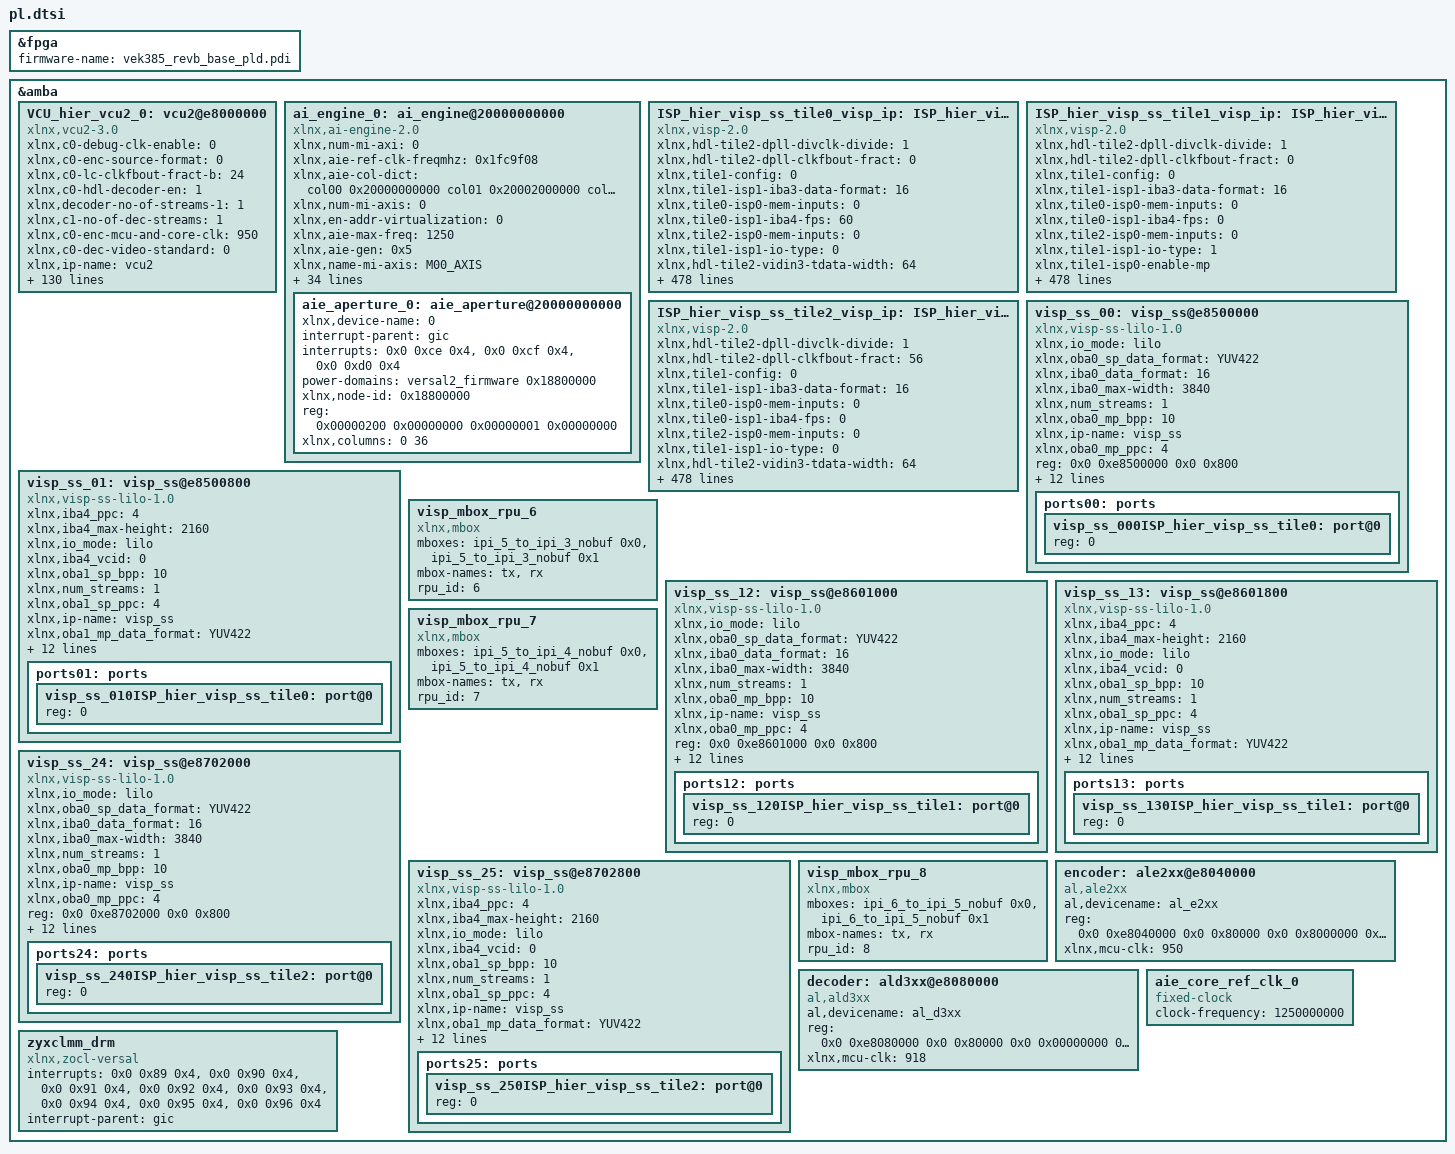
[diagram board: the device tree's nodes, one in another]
/dts-v1/;
/plugin/;
&fpga {
	firmware-name = "vek385_revb_base_pld.pdi";
};

&amba {
	VCU_hier_vcu2_0: vcu2@e8000000 {
		xlnx,c0-debug-clk-enable = <0>;
		xlnx,c0-enc-source-format = <0>;
		xlnx,c0-lc-clkfbout-fract-b = <24>;
		xlnx,c0-hdl-decoder-en = <1>;
		xlnx,decoder-no-of-streams-1 = <1>;
		xlnx,c1-no-of-dec-streams = <1>;
		xlnx,c0-enc-mcu-and-core-clk = <950>;
		xlnx,c0-dec-video-standard = <0>;
		xlnx,ip-name = "vcu2";
		#size-cells = <2>;
		reg = <0x0 0xe8000000 0x0 0x100000>;
		xlnx,encoder-resolution = "4096X2160";
		xlnx,c1-axi-slave-clk = <167>;
		xlnx,c0-enable-seperate-interrupts;
		#address-cells = <2>;
		xlnx,decoder-frequency-1 = <1050>;
		xlnx,c1-debug-clk-enable = <0>;
		xlnx,actual-c1-dec-mcu-and-core-clk = <0x36b6ce30>;
		xlnx,decoder-color-depth = <12>;
		xlnx,c1-lc-clkin-period-a = <0x7270e0>;
		xlnx,c0-dec-coding-type = <0>;
		xlnx,c0-enc-fps = <3>;
		xlnx,c0-hdl-enable-encoder-jtag = <0>;
		xlnx,decoder-resolution-1 = "4096X2160";
		xlnx,c1-lc-clkin-period-b = <0x7270e0>;
		xlnx,c1-hdl-enable-encoder-jtag = <0>;
		xlnx,c1-enc-fps = <3>;
		xlnx,c1-enable-encoder;
		xlnx,c1-dec-coding-type = <0>;
		xlnx,decoder-color-format-1 = <444>;
		xlnx,c1-hdl-encoder-en = <1>;
		xlnx,c0-en-debug-clk;
		xlnx,c0-enable-encoder-jtag;
		xlnx,c0-enc-color-format = <3>;
		xlnx,c1-lc-clkout-divide2-a = <4>;
		xlnx,actual-c1-axi-slave-clk = <0x9f2b120>;
		xlnx,enable-instance1 = <0>;
		xlnx,c1-lc-divclk-divide-a = <2>;
		xlnx,c1-lc-clkout-divide2-b = <3>;
		compatible = "xlnx,vcu2-3.0";
		xlnx,c0-dec-color-depth = <2>;
		xlnx,encoder-frame-per-second-1 = <60>;
		xlnx,c1-lc-divclk-divide-b = <1>;
		xlnx,c1-enc-source-format = <0>;
		xlnx,c1-dec-color-depth = <2>;
		xlnx,c0-dec-mcu-and-core-clk = <918>;
		xlnx,actual-c0-enc-mcu-and-core-clk = <0x389f8b60>;
		xlnx,c0-enable-encoder;
		xlnx,decoder-frequency = <1050>;
		xlnx,c0-hdl-enc-enable-low-latency-mode = <0>;
		xlnx,c0-hdl-encoder-en = <1>;
		xlnx,c1-hdl-enc-enable-low-latency-mode = <0>;
		xlnx,c0-no-of-enc-streams = <1>;
		xlnx,encoder-frequency = <950>;
		xlnx,encoder-coding-standard = "HEVC";
		xlnx,c1-dec-enable-low-latency-mode;
		xlnx,c0-enc-enable-low-latency-mode;
		xlnx,c0-enc-video-standard = <0>;
		xlnx,c1-enc-color-format = <3>;
		xlnx,c0-axi-slave-clk = <167>;
		xlnx,encoder-color-format = <444>;
		xlnx,c0-hdl-enable-decoder-jtag = <0>;
		xlnx,c1-hdl-enable-decoder-jtag = <0>;
		xlnx,c0-lc-clkfbout-mult-a = <55>;
		xlnx,new-param-for-image = <0>;
		xlnx,target-board = <0>;
		xlnx,c0-ref-clk = <0x7f27450>;
		xlnx,c0-lc-clkfbout-mult-b = <21>;
		xlnx,encoder-frame-per-second = <60>;
		xlnx,c1-ref-clk = <0x7f27450>;
		xlnx,c1-dec-frame-size = <5>;
		xlnx,c0-enable-decoder-jtag;
		xlnx,c0-dec-color-format = <3>;
		xlnx,num-of-instances = <0>;
		xlnx,c1-dec-video-standard = <0>;
		xlnx,encoder-color-format-1 = <444>;
		xlnx,actual-c0-axi-slave-clk = <0x9f2b120>;
		xlnx,name = "VCU_hier_vcu2_0";
		xlnx,enable-instance0-dpll;
		xlnx,c1-lc-clkout-divide3-a = <22>;
		xlnx,c1-lc-clkfbout-fract-a = <5>;
		xlnx,actual-c0-dec-mcu-and-core-clk = <0x36b6ce30>;
		xlnx,c1-lc-clkfbout-fract-b = <24>;
		xlnx,c1-enable-seperate-interrupts;
		xlnx,design-topology = <0>;
		xlnx,c0-dec-frame-size = <5>;
		xlnx,encoder-no-of-streams-1 = <1>;
		xlnx,c1-no-of-enc-streams = <1>;
		xlnx,c1-dec-color-format = <3>;
		xlnx,decoder-color-format = <444>;
		xlnx,c0-dec-fps = <3>;
		xlnx,decoder-frame-per-second = <60>;
		xlnx,decoder-coding-standard-1 = "HEVC";
		xlnx,c1-enable-decoder;
		xlnx,c1-dec-fps = <3>;
		xlnx,edk-iptype = "PERIPHERAL";
		xlnx,nsu-only;
		xlnx,encoder-frequency-1 = <950>;
		xlnx,encoder-coding-standard-1 = "HEVC";
		xlnx,encoder-color-depth = <12>;
		xlnx,c1-enc-mcu-and-core-clk = <950>;
		xlnx,c0-enc-coding-type = <0>;
		xlnx,c1-enc-frame-size = <5>;
		xlnx,c1-enc-coding-type = <0>;
		xlnx,c1-enable-encoder-jtag;
		xlnx,c0-lc-clkout-divide2-a = <4>;
		xlnx,c1-enc-video-standard = <0>;
		xlnx,c0-lc-clkout-divide2-b = <3>;
		xlnx,decoder-color-depth-1 = <12>;
		xlnx,c0-enable-decoder;
		xlnx,c0-hdl-dec-enable-low-latency-mode = <0>;
		xlnx,encoder-color-depth-1 = <12>;
		xlnx,c1-lc-clkfbout-mult-a = <55>;
		xlnx,c1-hdl-dec-enable-low-latency-mode = <0>;
		xlnx,c0-no-of-dec-streams = <1>;
		xlnx,c0-enc-color-depth = <2>;
		xlnx,decoder-coding-standard = "HEVC";
		xlnx,c1-lc-clkfbout-mult-b = <21>;
		xlnx,c1-enc-color-depth = <2>;
		xlnx,c0-dec-enable-low-latency-mode;
		xlnx,c0-enc-frame-size = <5>;
		xlnx,decoder-resolution = "4096X2160";
		xlnx,c1-en-debug-clk;
		xlnx,c1-enc-enable-low-latency-mode;
		xlnx,c0-lc-divclk-divide-a = <2>;
		xlnx,c0-lc-divclk-divide-b = <1>;
		xlnx,c0-lc-clkin-period-a = <0x7270e0>;
		xlnx,c1-hdl-decoder-en = <1>;
		xlnx,c1-dec-mcu-and-core-clk = <918>;
		xlnx,c0-lc-clkin-period-b = <0x7270e0>;
		xlnx,actual-c1-enc-mcu-and-core-clk = <0x389f8b60>;
		xlnx,decoder-no-of-streams = <1>;
		xlnx,c1-enable-decoder-jtag;
		xlnx,encoder-resolution-1 = "4096X2160";
		xlnx,encoder-no-of-streams = <1>;
		#clock-cells = <1>;
		xlnx,decoder-frame-per-second-1 = <60>;
		xlnx,c0-lc-clkout-divide3-a = <22>;
		xlnx,c0-lc-clkfbout-fract-a = <5>;
	};
	ai_engine_0: ai_engine@20000000000 {
		xlnx,num-mi-axi = <0>;
		compatible = "xlnx,ai-engine-2.0" , "xlnx,ai-engine-v2.0";
		xlnx,aie-ref-clk-freqmhz = <0x1fc9f08>;
		xlnx,aie-col-dict = "col00 0x20000000000 col01 0x20002000000 col02 0x20004000000 col03 0x20006000000 col04 0x20008000000 col05 0x2000A000000 col06 0x2000C000000 col07 0x2000E000000 col08 0x20010000000 col09 0x20012000000 col10 0x20014000000 col11 0x20016000000 col12 0x20018000000 col13 0x2001A000000 col14 0x2001C000000 col15 0x2001E000000 col16 0x20020000000 col17 0x20022000000 col18 0x20024000000 col19 0x20026000000 col20 0x20028000000 col21 0x2002A000000 col22 0x2002C000000 col23 0x2002E000000 col24 0x20030000000 col25 0x20032000000 col26 0x20034000000 col27 0x20036000000 col28 0x20038000000 col29 0x2003A000000 col30 0x2003C000000 col31 0x2003E000000 col32 0x20040000000 col33 0x20042000000 col34 0x20044000000 col35 0x20046000000";
		xlnx,num-mi-axis = <0>;
		xlnx,en-addr-virtualization = <0>;
		xlnx,aie-max-freq = <1250>;
		xlnx,aie-gen = /bits/ 8 <0x5>;
		xlnx,name-mi-axis = "M00_AXIS";
		xlnx,mem-rows = /bits/ 8 <1 2>;
		xlnx,mi-destid-pins;
		xlnx,ip-name = "ai_engine";
		#size-cells = <2>;
		xlnx,num-si-axi = <1>;
		xlnx,fast-pm-write;
		reg = <0x00000200 0x00000000 0x00000001 0x00000000>;
		clocks = <&aie_core_ref_clk_0>;
		xlnx,num-noc-axis-clks = <0>;
		ranges;
		xlnx,num-clks = <0>;
		xlnx,partition-enabled = <0>;
		#address-cells = <2>;
		xlnx,num-si-axis = <0>;
		xlnx,name-mi-axi = "M00_AXI";
		xlnx,num-column = <1>;
		xlnx,aie-core-ref-ctrl-freqmhz = <1250>;
		xlnx,clk-names = "aclk0";
		xlnx,name-si-axis = "S00_AXIS";
		xlnx,fast-dm-write;
		xlnx,edk-iptype = "PERIPHERAL";
		xlnx,selected-nsu = <0>;
		xlnx,available-nsu = "NOC2_NSU128_X0Y6 0x20006000000 NOC2_NSU128_X2Y6 0x2000e000000 NOC2_NSU128_X3Y6 0x20016000000 NOC2_NSU128_X8Y7 0x2001e000000 NOC2_NSU128_X9Y6 0x20026000000 NOC2_NSU128_X10Y7 0x2002e000000 NOC2_NSU128_X11Y6 0x20036000000 NOC2_NSU128_X12Y6 0x2003e000000 NOC2_NSU128_X13Y6 0x20046000000";
		clock-names = "aclk0";
		power-domains = <&versal2_firmware 0x18800000>;
		xlnx,num-trig-in = <0>;
		xlnx,nsu-dict = "NOC2_NSU128_X0Y6 0x20006000000 NOC2_NSU128_X2Y6 0x2000e000000 NOC2_NSU128_X3Y6 0x20016000000 NOC2_NSU128_X8Y7 0x2001e000000 NOC2_NSU128_X9Y6 0x20026000000 NOC2_NSU128_X10Y7 0x2002e000000 NOC2_NSU128_X11Y6 0x20036000000 NOC2_NSU128_X12Y6 0x2003e000000 NOC2_NSU128_X13Y6 0x20046000000";
		xlnx,en-ext-rst = <0>;
		xlnx,num-trig-out = <0>;
		xlnx,core-rows = /bits/ 8 <3 4>;
		xlnx,shim-rows = /bits/ 8 <0 1>;
		xlnx,name-si-axi = "S00_AXI";
		xlnx,start-column = <0>;
		xlnx,name = "ai_engine_0";
		xlnx,aie-site = "AIE2PS";
		aie_aperture_0: aie_aperture@20000000000 {
			xlnx,device-name = <0>;
			interrupt-parent = <&gic>;
			interrupts = <0x0 0xce 0x4>, <0x0 0xcf 0x4>, <0x0 0xd0 0x4>;
			#address-cells = <2>;
			power-domains = <&versal2_firmware 0x18800000>;
			xlnx,node-id = <0x18800000>;
			#size-cells = <2>;
			interrupt-names = "interrupt1" , "interrupt2" , "interrupt3";
			reg = <0x00000200 0x00000000 0x00000001 0x00000000>;
			xlnx,columns = < 0 36 >;
		};
	};
	ISP_hier_visp_ss_tile0_visp_ip: ISP_hier_visp_ss_tile0_visp_ip@e8500000 {
		xlnx,hdl-tile2-dpll-divclk-divide = <1>;
		xlnx,hdl-tile2-dpll-clkfbout-fract = <0>;
		xlnx,tile1-config = <0>;
		xlnx,tile1-isp1-iba3-data-format = <16>;
		xlnx,tile0-isp0-mem-inputs = <0>;
		xlnx,tile0-isp1-iba4-fps = <60>;
		xlnx,tile2-isp0-mem-inputs = <0>;
		xlnx,tile1-isp1-io-type = <0>;
		xlnx,hdl-tile2-vidin3-tdata-width = <64>;
		xlnx,hdl-tile0-vidin0-tuser-width = <96>;
		xlnx,debug-tile2-iba3-bypass = <0>;
		xlnx,debug-tile0-clk-src-dpll;
		xlnx,tile1-isp0-iba3-vcid = <0>;
		xlnx,tile1-isp0-oba0-mp-y;
		xlnx,tile2-isp0-iba1-res-hor = <3840>;
		xlnx,tile0-common-iba3-ppc = <4>;
		reg = <0x0 0xe8500000 0x0 0x100000>;
		xlnx,tile0-isp0-iba3-data-format = <16>;
		xlnx,tile1-isp0-iba1-fps = <0>;
		xlnx,tile2-vidout01-tdata-width = <120>;
		xlnx,tile2-isp0-iba2-data-format = <16>;
		xlnx,hdl-tile0-dpll-clkin-period = <0x72719b>;
		xlnx,tile2-common-iba3-ppc = <4>;
		xlnx,tile1-isp1-oba1-mp-bpp = <10>;
		xlnx,tile0-enable;
		xlnx,tile1-isp0-iba0-res-ver = <2160>;
		xlnx,hdl-tile1-vidin0-tdata-width = <64>;
		xlnx,tile0-dpll-divclk-divide = <1>;
		xlnx,tile0-isp0-core-clk = <0x23988c80>;
		xlnx,tile1-isp0-iba0-vcid = <0>;
		xlnx,hdl-tile1-vidout02-bpp = <10>;
		xlnx,hdl-tile0-vidin4-ppc = <4>;
		xlnx,debug-tile1-apb-clk-src-axi;
		xlnx,tile2-isp0-netfps = <0>;
		xlnx,tile2-isp1-oba1-sp-y;
		xlnx,tile0-isp1-oba1-ppc = <4>;
		xlnx,tile0-vidin3-tdata-width = <64>;
		xlnx,hdl-tile2-isp1-iba4-res-hor = <3840>;
		xlnx,tile0-isp1-iba4-res-hor = <3840>;
		xlnx,tile1-common-iba3-res-ver = <2160>;
		xlnx,hdl-tile1-vidout11-bpp = <10>;
		xlnx,debug-tile2-iba1-bypass = <0>;
		xlnx,hdl-tile1-vidout12-ppc = <4>;
		xlnx,tile2-isp0-iba2-vcid = <0>;
		xlnx,tile2-isp0-oba0-sp-rgb888;
		xlnx,tile0-isp0-iba3-fps = <0>;
		xlnx,hdl-tile1-vidin3-data-format = <16>;
		xlnx,tile1-vidin0-tuser-width = <96>;
		xlnx,tile2-isp0-iba1-res-ver = <2160>;
		xlnx,tile0-isp1-io-type = <1>;
		xlnx,tile0-isp1-mem-inputs = <0>;
		xlnx,tile1-isp0-actual-core-clk = <0x23c31ef0>;
		xlnx,hdl-llpath0-tile = <3>;
		xlnx,tile0-common-iba3-data-format = <16>;
		xlnx,tile0-isp0-oba0-sp-bpp = <10>;
		xlnx,tile0-isp1-iba4-ppc = <4>;
		xlnx,tile1-isp0-oba0-sp-y;
		xlnx,debug-clock-gate = <0>;
		xlnx,tile2-isp1-mem-inputs = <0>;
		xlnx,hdl-tile2-isp1-iba4-vcid = <0>;
		xlnx,hdl-tile0-vidin0-data-format = <16>;
		xlnx,tile2-vidin0-tdata-width = <64>;
		xlnx,tile2-common-iba3-res-hor = <3840>;
		xlnx,tile0-isp1-oba1-sp-rgb888;
		xlnx,tile2-ref-clk = <0x7f27450>;
		xlnx,name = "ISP_hier_visp_ss_tile0_visp_ip";
		xlnx,tile1-isp1-oba1-sp-yuv422;
		xlnx,tile1-isp0-iba1-ppc = <4>;
		xlnx,hdl-tile2-isp0-iba0-res-hor = <3840>;
		xlnx,hdl-tile0-vidout02-bpp = <10>;
		xlnx,tile0-isp0-iba0-res-hor = <3840>;
		xlnx,hdl-tile2-vidin2-tdata-width = <64>;
		xlnx,debug-tile1-iba3-bypass = <0>;
		xlnx,tile0-isp0-oba0-ppc = <4>;
		xlnx,tile0-isp1-iba4-res-ver = <2160>;
		xlnx,hdl-tile1-vidin4-ppc = <4>;
		xlnx,tile0-isp0-iba2-data-format = <16>;
		xlnx,tile0-isp0-oba0-mp-bpp = <10>;
		xlnx,is-hierarchy;
		xlnx,tile2-isp0-iba1-data-format = <16>;
		xlnx,hdl-tile1-dpll-clkfbout-mult = <18>;
		xlnx,hdl-tile0-vidin1-ppc = <4>;
		xlnx,tile0-dpll-clkout3-divide = <6>;
		xlnx,hdl-tile0-vidout11-bpp = <10>;
		xlnx,hdl-tile2-isp-core-1-resolution-mp = <4>;
		xlnx,tile1-isp0-netfps = <0>;
		xlnx,hdl-tile0-vidout12-ppc = <4>;
		xlnx,tile2-isp0-oba0-sp-bpp = <10>;
		xlnx,tile0-vidin2-tdata-width = <64>;
		xlnx,hdl-tile1-isp0-iba0-vcid = <0>;
		xlnx,tile0-isp0-oba0-mp-yuv422;
		xlnx,hdl-tile1-isp-core-0-resolution-mp = <4>;
		xlnx,tile2-common-iba3-res-ver = <2160>;
		xlnx,tile0-isp0-iba3-ppc = <4>;
		xlnx,debug-tile1-iba1-bypass = <0>;
		xlnx,tile1-isp1-iba4-fps = <0>;
		xlnx,hdl-tile0-vidin4-tdata-width = <64>;
		xlnx,tile0-isp0-iba0-fps = <60>;
		xlnx,tile1-isp0-iba1-res-hor = <3840>;
		xlnx,llpath0-tile = <3>;
		xlnx,tile2-isp0-oba0-mp-bpp = <10>;
		xlnx,tile2-isp0-iba1-fps = <0>;
		xlnx,tile0-isp0-iba0-res-ver = <2160>;
		xlnx,hdl-tile1-vidin2-data-format = <16>;
		xlnx,ppc-converter-s2-isp = <0>;
		xlnx,hdl-tile2-vidin4-tuser-width = <96>;
		xlnx,tile1-isp0-core-clk = "600.00";
		xlnx,hdl-tile0-dpll-clkout-divide2 = <6>;
		xlnx,tile2-dpll-clkfbout-mult = <18>;
		xlnx,hdl-tile2-vidin4-ppc = <4>;
		xlnx,hdl-tile1-isp1-iba4-res-hor = <3840>;
		xlnx,hdl-tile0-dpll-clkout-divide3 = <6>;
		xlnx,tile1-isp1-oba1-sp-rgb888;
		xlnx,tile1-isp1-oba1-ppc = <4>;
		xlnx,tile1-isp1-oba1-mp-y;
		xlnx,tile1-isp1-iba4-vcid = <0>;
		xlnx,tile2-isp1-oba1-sp-yuv422;
		xlnx,hdl-tile1-vidin1-ppc = <4>;
		xlnx,llpath0-clk = <150>;
		xlnx,hdl-tile2-vidin1-tdata-width = <64>;
		xlnx,debug-tile0-iba3-bypass = <0>;
		xlnx,tile2-isp0-rpu = <8>;
		xlnx,tile2-isp0-actual-core-clk = <0x23c31ef0>;
		xlnx,tile0-isp0-iba1-data-format = <16>;
		xlnx,tile0-vidin4-tuser-width = <96>;
		xlnx,tile2-isp0-iba0-data-format = <16>;
		xlnx,hdl-tile1-isp-core-0-frame-rate = <30>;
		xlnx,tile2-isp0-iba2-res-hor = <3840>;
		xlnx,hdl-llpath1-oba = <0>;
		xlnx,tile1-vidin4-tdata-width = <64>;
		xlnx,tile1-isp0-iba3-fps = <0>;
		xlnx,tile1-isp0-iba1-res-ver = <2160>;
		xlnx,tile0-isp0-netfps = <60>;
		xlnx,tile1-dpll-clkout3-divide = <4>;
		xlnx,tile0-isp0-enable-mp;
		xlnx,llpath1-oba = <0>;
		xlnx,tile0-isp0-iba3-vcid = <0>;
		xlnx,tile0-isp0-oba0-mp-y;
		xlnx,tile0-vidin1-tdata-width = <64>;
		xlnx,tile1-isp1-iba4-ppc = <4>;
		xlnx,tile1-isp1-live-inputs = <0>;
		xlnx,tile2-dpll-clkin-period = <0x72719b>;
		xlnx,hdl-tile0-dpll-divclk-divide = <1>;
		xlnx,tile0-isp0-iba0-ppc = <4>;
		xlnx,tile0-isp0-oba0-mp-rgb888;
		xlnx,tile2-isp1-iba3-vcid = <0>;
		xlnx,tile1-isp0-oba0-mp-yuv422;
		xlnx,hdl-tile1-isp0-iba0-res-hor = <3840>;
		xlnx,debug-tile0-iba1-bypass = <0>;
		xlnx,tile2-isp0-iba1-ppc = <4>;
		xlnx,tile0-isp0-iba0-vcid = <0>;
		xlnx,tile0-dpll-clkfbout-fract = <56>;
		xlnx,tile2-isp1-iba4-data-format = <16>;
		xlnx,tile0-isp1-rpu = <6>;
		xlnx,tile1-common-iba3-vcid = <0>;
		xlnx,hdl-tile2-vidout01-bpp = <10>;
		xlnx,hdl-tile2-vidin4-data-format = <16>;
		xlnx,hdl-tile0-vidin3-tdata-width = <64>;
		xlnx,tile0-isp1-core-clk = <0x23988c80>;
		xlnx,hdl-tile0-vidout12-tdata-width = <120>;
		xlnx,tile0-isp0-oba0-sp-ir;
		xlnx,hdl-tile2-vidout02-ppc = <4>;
		xlnx,hdl-tile2-isp-core-0-no-of-sensors = <0>;
		xlnx,tile1-isp1-oba1-sp-y;
		xlnx,tile1-isp0-oba0-ppc = <4>;
		xlnx,tile2-isp0-oba0-sp-ir;
		xlnx,hdl-tile1-vidin1-data-format = <16>;
		xlnx,hdl-tile2-vidin1-ppc = <4>;
		xlnx,tile2-isp0-iba2-res-ver = <2160>;
		xlnx,tile1-isp0-iba2-vcid = <0>;
		xlnx,hdl-tile2-vidout11-ppc = <4>;
		xlnx,hdl-tile1-vidin0-tuser-width = <96>;
		xlnx,hdl-tile1-dpll-clkout-divide2 = <4>;
		xlnx,tile0-isp1-oba1-sp-ir;
		xlnx,hdl-tile1-dpll-clkout-divide3 = <4>;
		xlnx,hdl-tile1-isp-core-1-frame-rate = <30>;
		xlnx,tile2-isp1-oba1-sp-rgb888;
		xlnx,tile2-isp1-oba1-sp-ir;
		xlnx,tile0-isp1-iba3-fps = <0>;
		xlnx,hdl-llpath0-tdest-val = <0>;
		xlnx,hdl-tile2-vidin0-tdata-width = <64>;
		xlnx,hdl-tile1-isp-core-1-resolution-mp = <4>;
		xlnx,hdl-llpath1-iba = <0>;
		xlnx,tile0-isp0-oba0-sp-y;
		xlnx,tile1-dpll-divclk-divide = <1>;
		xlnx,tile1-isp0-iba3-ppc = <4>;
		xlnx,tile2-isp1-iba4-fps = <0>;
		xlnx,tile0-isp0-iba0-data-format = <16>;
		xlnx,hdl-tile1-isp1-iba4-vcid = <0>;
		xlnx,tile0-isp0-iba1-res-hor = <3840>;
		xlnx,llpath1-iba = <0>;
		xlnx,tile1-isp0-iba0-fps = <0>;
		xlnx,tile1-vidin3-tdata-width = <64>;
		xlnx,hdl-tile0-isp-core-0-resolution-mp = <8>;
		xlnx,debug-tile2-expose-allintf-allports = <0>;
		xlnx,hdl-tile1-vidout01-bpp = <10>;
		xlnx,edk-iptype = "PERIPHERAL";
		xlnx,hdl-tile0-vidout02-tdata-width = <120>;
		xlnx,hdl-tile0-vidin3-ppc = <4>;
		xlnx,tile2-dpll-clkout3-divide = <4>;
		xlnx,tile0-vidin0-tdata-width = <64>;
		xlnx,tile1-isp0-live-inputs = <0>;
		xlnx,hdl-tile1-vidout02-ppc = <4>;
		xlnx,tile2-isp0-iba1-vcid = <0>;
		xlnx,tile2-isp0-core-clk = "600.00";
		xlnx,hdl-tile0-isp1-iba4-res-hor = <3840>;
		xlnx,tile1-common-iba3-fps = <0>;
		xlnx,tile1-isp0-oba0-mp-rgb888;
		xlnx,tile2-isp1-oba1-ppc = <4>;
		xlnx,tile0-isp1-iba4-data-format = <16>;
		xlnx,tile2-isp1-iba3-res-hor = <3840>;
		xlnx,tile2-isp1-iba3-data-format = <16>;
		xlnx,tile2-isp0-oba0-mp-yuv422;
		xlnx,hdl-tile2-vidin3-data-format = <16>;
		xlnx,hdl-tile0-vidin2-tdata-width = <64>;
		xlnx,tile2-vidin0-tuser-width = <96>;
		xlnx,tile0-isp1-actual-core-clk = <0x2398b390>;
		xlnx,tile1-dpll-clkfbout-fract = <0>;
		xlnx,hdl-tile0-vidout11-tdata-width = <120>;
		xlnx,config-only;
		xlnx,hdl-tile1-vidout11-ppc = <4>;
		xlnx,tile0-isp1-oba1-sp-bpp = <10>;
		xlnx,hdl-tile1-vidin0-data-format = <16>;
		xlnx,hdl-tile0-isp0-iba0-vcid = <0>;
		xlnx,tile0-isp0-iba2-fps = <0>;
		xlnx,tile1-isp0-iba2-res-hor = <3840>;
		xlnx,tile1-isp0-iba3-data-format = <16>;
		xlnx,tile0-isp0-iba1-res-ver = <2160>;
		xlnx,hdl-tile0-enabledpll;
		xlnx,tile2-isp0-iba3-fps = <0>;
		xlnx,tile2-config = <0>;
		xlnx,tile0-isp1-oba1-mp-yuv422;
		xlnx,tile0-isp1-iba3-ppc = <4>;
		xlnx,tile1-dpll-clkin-period = <0x72719b>;
		xlnx,hdl-tile1-vidout12-tdata-width = <120>;
		xlnx,tile2-isp1-iba4-ppc = <4>;
		xlnx,debug-tile2-iba4-bypass = <0>;
		xlnx,hdl-tile2-dpll-clkout-divide2 = <4>;
		xlnx,tile0-isp1-oba1-mp-bpp = <10>;
		xlnx,tile0-vidout12-tdata-width = <120>;
		xlnx,tile1-isp0-iba0-ppc = <4>;
		xlnx,hdl-tile2-dpll-clkout-divide3 = <4>;
		xlnx,hdl-tile0-isp0-iba0-res-hor = <3840>;
		xlnx,hdl-tile0-vidout01-bpp = <10>;
		xlnx,hdl-tile2-dpll-clkfbout-mult = <18>;
		xlnx,tile1-isp0-mem-inputs = <0>;
		xlnx,hdl-tile0-vidout02-ppc = <4>;
		xlnx,hdl-tile1-vidin3-ppc = <4>;
		xlnx,tile1-isp1-core-clk = "600.00";
		xlnx,tile2-isp1-netfps = <0>;
		xlnx,tile2-isp1-iba3-res-ver = <2160>;
		xlnx,hdl-tile2-isp-core-1-no-of-sensors = <0>;
		xlnx,tile2-isp0-oba0-ppc = <4>;
		xlnx,tile1-vidin2-tdata-width = <64>;
		xlnx,tile0-isp1-iba4-vcid = <0>;
		xlnx,tile0-isp1-oba1-mp-y;
		xlnx,tile2-isp1-oba1-sp-bpp = <10>;
		xlnx,tile0-config = <0>;
		xlnx,tile1-common-iba3-ppc = <4>;
		xlnx,hdl-tile0-vidin0-ppc = <4>;
		xlnx,tile2-isp0-iba3-res-hor = <3840>;
		xlnx,hdl-tile0-vidin4-tuser-width = <96>;
		xlnx,hdl-tile0-vidout01-tdata-width = <120>;
		xlnx,debug-tile0-expose-scandfx-ports = <0>;
		xlnx,tile1-isp0-iba2-res-ver = <2160>;
		xlnx,hdl-tile0-vidout11-ppc = <4>;
		xlnx,debug-tile0-apb-clk-src-axi;
		xlnx,tile0-dpll-clkfbout-mult = <26>;
		xlnx,hdl-tile1-isp-core-0-no-of-sensors = <0>;
		xlnx,debug-tile2-iba2-bypass = <0>;
		xlnx,hdl-tile1-vidin4-tdata-width = <64>;
		xlnx,debug-tile2-apb-clk-src-axi;
		xlnx,tile0-isp1-iba3-data-format = <16>;
		xlnx,tile2-isp0-oba0-mp-rgb888;
		compatible = "xlnx,visp-2.0";
		xlnx,tile0-isp0-iba2-ppc = <4>;
		xlnx,hdl-tile2-vidin2-data-format = <16>;
		xlnx,hdl-tile0-vidin1-tdata-width = <64>;
		xlnx,tile2-isp1-oba1-mp-bpp = <10>;
		xlnx,tile1-isp1-iba3-fps = <0>;
		xlnx,hdl-tile1-enabledpll;
		xlnx,tile2-isp0-iba3-ppc = <4>;
		xlnx,tile2-dpll-clkfbout-fract = <0>;
		xlnx,hdl-tile1-vidout02-tdata-width = <120>;
		xlnx,tile2-isp0-iba0-fps = <0>;
		xlnx,tile0-vidout02-tdata-width = <120>;
		xlnx,tile1-isp0-iba2-data-format = <16>;
		xlnx,tile1-isp1-iba3-vcid = <0>;
		xlnx,ppc-converter-s1-isp = <0>;
		xlnx,tile0-isp1-oba1-mp-rgb888;
		xlnx,hdl-tile0-isp-core-1-resolution-mp = <8>;
		xlnx,debug-tile2-iba0-bypass = <0>;
		xlnx,tile1-isp1-oba1-mp-yuv422;
		xlnx,tile1-isp1-rpu = <7>;
		xlnx,tile1-isp1-actual-core-clk = <0x23c31ef0>;
		xlnx,tile1-isp1-mem-inputs = <0>;
		xlnx,hdl-tile1-vidout11-tdata-width = <120>;
		xlnx,tile2-isp0-iba3-res-ver = <2160>;
		xlnx,tile0-isp1-oba1-sp-y;
		xlnx,hdl-tile2-vidout12-bpp = <10>;
		xlnx,hdl-tile2-vidin3-ppc = <4>;
		xlnx,debug-tile1-iba4-bypass = <0>;
		xlnx,tile2-common-iba3-data-format = <16>;
		xlnx,tile1-vidin4-tuser-width = <96>;
		xlnx,tile0-ref-clk = <0x7f27450>;
		xlnx,tile0-vidout11-tdata-width = <120>;
		xlnx,tile1-isp1-iba3-res-hor = <3840>;
		xlnx,hdl-tile1-vidin0-ppc = <4>;
		xlnx,hdl-tile0-vidin4-data-format = <16>;
		xlnx,tile2-vidin4-tdata-width = <64>;
		xlnx,tile0-isp0-iba2-vcid = <0>;
		xlnx,tile1-isp0-oba0-sp-bpp = <10>;
		xlnx,tile1-isp1-netfps = <0>;
		xlnx,tile1-vidin1-tdata-width = <64>;
		xlnx,tile0-isp0-iba2-res-hor = <3840>;
		xlnx,hdl-tile2-vidout12-tdata-width = <120>;
		xlnx,hdl-tile1-dpll-divclk-divide = <1>;
		xlnx,hdl-llpath0-oba = <0>;
		xlnx,debug-tile1-expose-allintf-allports = <0>;
		xlnx,tile1-isp0-iba2-fps = <0>;
		xlnx,tile1-vidout12-tdata-width = <120>;
		xlnx,hdl-tile2-dpll-clkin-period = <0x72719b>;
		xlnx,speedgrade = "-2mp";
		xlnx,llpath0-oba = <0>;
		xlnx,hdl-tile2-enabledpll;
		xlnx,hdl-tile0-isp1-iba4-vcid = <0>;
		xlnx,debug-tile1-iba2-bypass = <0>;
		xlnx,tile2-isp0-io-type = <0>;
		xlnx,tile0-dpll-clkin-period = <0x72719b>;
		xlnx,tile1-isp1-iba3-ppc = <4>;
		xlnx,hdl-tile1-vidin3-tdata-width = <64>;
		xlnx,tile1-isp0-oba0-mp-bpp = <10>;
		xlnx,hdl-tile2-vidin1-data-format = <16>;
		xlnx,hdl-tile0-vidin0-tdata-width = <64>;
		xlnx,tile2-isp0-iba0-ppc = <4>;
		xlnx,tile0-dpll-clkout2-divide = <6>;
		xlnx,tile0-isp0-rpu = <6>;
		xlnx,tile2-isp1-iba4-res-hor = <3840>;
		xlnx,hdl-tile1-vidout01-tdata-width = <120>;
		xlnx,debug-tile1-expose-scandfx-ports = <0>;
		xlnx,tile1-isp0-iba1-vcid = <0>;
		xlnx,hdl-tile2-vidout01-ppc = <4>;
		xlnx,hdl-tile1-vidout12-bpp = <10>;
		xlnx,tile1-isp1-iba3-res-ver = <2160>;
		xlnx,tile2-isp1-core-clk = "600.00";
		xlnx,tile0-isp0-oba0-sp-yuv422;
		xlnx,tile0-vidout01-tdata-width = <120>;
		xlnx,tile1-isp0-iba1-data-format = <16>;
		xlnx,hdl-tile2-vidin0-tuser-width = <96>;
		xlnx,ppc-converter-num-streams = <0>;
		xlnx,tile1-isp0-iba3-res-hor = <3840>;
		xlnx,hdl-tile2-isp-core-0-frame-rate = <30>;
		xlnx,llpath1-delay = <278>;
		xlnx,debug-tile1-iba0-bypass = <0>;
		xlnx,tile1-isp1-oba1-mp-rgb888;
		xlnx,tile0-isp0-iba2-res-ver = <2160>;
		xlnx,hdl-tile2-vidin0-ppc = <4>;
		xlnx,tile2-isp1-oba1-mp-yuv422;
		xlnx,tile2-dpll-divclk-divide = <1>;
		xlnx,debug-tile0-iba4-bypass = <0>;
		xlnx,hdl-tile2-vidout02-tdata-width = <120>;
		xlnx,hdl-tile1-isp-core-1-no-of-sensors = <0>;
		xlnx,hdl-tile0-dpll-clkfbout-fract = <56>;
		xlnx,tile2-isp0-oba0-mp-y;
		xlnx,tile2-isp0-iba3-vcid = <0>;
		xlnx,tile1-vidout02-tdata-width = <120>;
		xlnx,hdl-tile0-vidin3-data-format = <16>;
		xlnx,tile2-vidin3-tdata-width = <64>;
		xlnx,tile0-vidin0-tuser-width = <96>;
		xlnx,hdl-llpath0-iba = <0>;
		xlnx,tile1-isp0-iba2-ppc = <4>;
		xlnx,tile2-isp1-iba3-fps = <0>;
		xlnx,tile1-isp0-io-type = <0>;
		xlnx,hdl-tile0-isp-core-0-no-of-sensors = <1>;
		xlnx,tile2-isp0-iba0-vcid = <0>;
		xlnx,tile0-isp1-live-inputs = <1>;
		xlnx,tile0-isp1-netfps = <60>;
		xlnx,hdl-llpath1-tile = <3>;
		xlnx,tile2-isp1-actual-core-clk = <0x23c31ef0>;
		xlnx,tile1-vidin0-tdata-width = <64>;
		xlnx,llpath0-iba = <0>;
		xlnx,hdl-tile2-vidout11-tdata-width = <120>;
		xlnx,hdl-llpath1-delay = <41>;
		xlnx,tile2-isp0-iba0-res-hor = <3840>;
		xlnx,ip-name = "visp";
		xlnx,tile2-isp1-iba4-res-ver = <2160>;
		xlnx,tile1-vidout11-tdata-width = <120>;
		xlnx,llpath0-delay = <278>;
		xlnx,tile0-common-iba3-vcid = <0>;
		xlnx,hdl-tile0-vidin2-ppc = <4>;
		xlnx,debug-tile0-iba2-bypass = <0>;
		xlnx,hdl-tile1-vidout01-ppc = <4>;
		xlnx,hdl-tile1-vidin2-tdata-width = <64>;
		xlnx,hdl-tile0-vidout12-bpp = <10>;
		xlnx,tile1-isp0-iba3-res-ver = <2160>;
		xlnx,hdl-tile2-vidin0-data-format = <16>;
		xlnx,tile0-isp1-iba3-res-hor = <3840>;
		xlnx,hdl-tile0-dpll-clkfbout-mult = <26>;
		xlnx,hdl-tile2-isp-core-1-frame-rate = <30>;
		xlnx,tile2-vidout12-tdata-width = <120>;
		xlnx,tile1-dpll-clkout2-divide = <4>;
		xlnx,hdl-llpath0-delay = <41>;
		xlnx,tile2-isp0-oba0-sp-y;
		xlnx,tile0-isp0-oba0-sp-rgb888;
		xlnx,tile1-isp0-iba0-data-format = <16>;
		xlnx,tile2-isp1-live-inputs = <0>;
		xlnx,tile0-isp0-iba1-fps = <0>;
		xlnx,tile1-isp0-oba0-sp-ir;
		xlnx,hdl-tile0-isp-core-0-frame-rate = <60>;
		xlnx,tile1-isp0-oba0-sp-yuv422;
		xlnx,debug-tile2-clk-src-dpll;
		xlnx,debug-tile0-iba0-bypass = <0>;
		xlnx,tile2-isp0-iba2-fps = <0>;
		xlnx,hdl-tile1-dpll-clkin-period = <0x72719b>;
		xlnx,tile2-isp0-iba0-res-ver = <2160>;
		xlnx,tile0-isp0-io-type = <1>;
		xlnx,tile2-isp1-oba1-mp-rgb888;
		xlnx,ppc-converter-s3-isp = <0>;
		xlnx,tile2-common-iba3-vcid = <0>;
		xlnx,tile0-common-iba3-res-hor = <3840>;
		xlnx,hdl-tile2-vidout01-tdata-width = <120>;
		xlnx,debug-tile2-expose-scandfx-ports = <0>;
		xlnx,tile2-isp1-iba3-ppc = <4>;
		xlnx,tile0-isp1-enable-mp;
		xlnx,tile1-common-iba3-data-format = <16>;
		xlnx,tile0-isp1-iba3-vcid = <0>;
		xlnx,tile1-vidout01-tdata-width = <120>;
		xlnx,tile1-ref-clk = <0x7f27450>;
		xlnx,hdl-tile1-dpll-clkfbout-fract = <0>;
		xlnx,hdl-tile0-vidin2-data-format = <16>;
		xlnx,tile2-vidin2-tdata-width = <64>;
		xlnx,tile1-isp1-oba1-sp-ir;
		xlnx,llpath1-tile = <3>;
		xlnx,tile1-isp1-iba4-data-format = <16>;
		xlnx,tile1-isp1-iba4-res-hor = <3840>;
		xlnx,hdl-tile1-vidin4-tuser-width = <96>;
		xlnx,hdl-tile0-vidout01-ppc = <4>;
		xlnx,tile0-isp0-live-inputs = <1>;
		xlnx,hdl-tile1-vidin2-ppc = <4>;
		xlnx,llpath1-clk = <150>;
		xlnx,tile0-isp1-iba3-res-ver = <2160>;
		xlnx,tile2-isp1-rpu = <8>;
		xlnx,tile1-dpll-clkfbout-mult = <18>;
		xlnx,hdl-tile2-vidin4-tdata-width = <64>;
		xlnx,debug-tile0-expose-allintf-allports = <0>;
		xlnx,tile0-isp0-iba3-res-hor = <3840>;
		xlnx,hdl-tile2-isp0-iba0-vcid = <0>;
		xlnx,tile2-vidout02-tdata-width = <120>;
		xlnx,tile2-isp0-iba3-data-format = <16>;
		xlnx,hdl-tile1-vidin1-tdata-width = <64>;
		xlnx,tile2-isp1-io-type = <0>;
		xlnx,tile0-common-iba3-fps = <0>;
		xlnx,hdl-tile0-enable;
		xlnx,debug-tile1-clk-src-dpll;
		xlnx,tile2-common-iba3-fps = <0>;
		xlnx,hdl-tile0-isp-core-1-frame-rate = <60>;
		xlnx,tile0-isp0-iba1-ppc = <4>;
		xlnx,tile0-common-iba3-res-ver = <2160>;
		xlnx,tile0-vidin4-tdata-width = <64>;
		xlnx,tile2-vidout11-tdata-width = <120>;
		xlnx,tile0-isp0-actual-core-clk = <0x2398b390>;
		xlnx,hdl-llpath1-tdest-val = <0>;
		xlnx,tile2-isp0-iba2-ppc = <4>;
		xlnx,tile2-dpll-clkout2-divide = <4>;
		xlnx,hdl-tile2-vidout02-bpp = <10>;
		xlnx,hdl-tile0-isp-core-1-no-of-sensors = <1>;
		xlnx,tile2-isp0-live-inputs = <0>;
		xlnx,tile1-isp0-iba0-res-hor = <3840>;
		xlnx,tile1-isp0-oba0-sp-rgb888;
		xlnx,tile1-isp1-iba4-res-ver = <2160>;
		xlnx,tile2-vidin4-tuser-width = <96>;
		xlnx,tile2-isp0-oba0-sp-yuv422;
		xlnx,ppc-converter-s0-isp = <0>;
		xlnx,tile2-isp1-oba1-mp-y;
		xlnx,tile2-isp1-iba4-vcid = <0>;
		xlnx,hdl-tile2-isp-core-0-resolution-mp = <4>;
		xlnx,hdl-tile1-vidin4-data-format = <16>;
		xlnx,tile0-isp0-iba1-vcid = <0>;
		xlnx,tile0-isp0-iba3-res-ver = <2160>;
		xlnx,tile1-isp0-rpu = <7>;
		xlnx,hdl-tile2-vidout11-bpp = <10>;
		xlnx,hdl-tile2-vidin2-ppc = <4>;
		xlnx,tile1-common-iba3-res-hor = <3840>;
		xlnx,hdl-tile2-vidout12-ppc = <4>;
		xlnx,hdl-tile0-vidin1-data-format = <16>;
		xlnx,tile2-vidin1-tdata-width = <64>;
		xlnx,tile1-isp1-oba1-sp-bpp = <10>;
		xlnx,tile0-isp1-oba1-sp-yuv422;
	};
	ISP_hier_visp_ss_tile1_visp_ip: ISP_hier_visp_ss_tile1_visp_ip@e8600000 {
		xlnx,hdl-tile2-dpll-divclk-divide = <1>;
		xlnx,hdl-tile2-dpll-clkfbout-fract = <0>;
		xlnx,tile1-config = <0>;
		xlnx,tile1-isp1-iba3-data-format = <16>;
		xlnx,tile0-isp0-mem-inputs = <0>;
		xlnx,tile0-isp1-iba4-fps = <0>;
		xlnx,tile2-isp0-mem-inputs = <0>;
		xlnx,tile1-isp1-io-type = <1>;
		xlnx,tile1-isp0-enable-mp;
		xlnx,hdl-tile2-vidin3-tdata-width = <64>;
		xlnx,hdl-tile0-vidin0-tuser-width = <96>;
		xlnx,debug-tile2-iba3-bypass = <0>;
		xlnx,debug-tile0-clk-src-dpll;
		xlnx,tile1-isp0-iba3-vcid = <0>;
		xlnx,tile1-isp0-oba0-mp-y;
		xlnx,tile2-isp0-iba1-res-hor = <3840>;
		xlnx,tile0-common-iba3-ppc = <4>;
		reg = <0x0 0xe8600000 0x0 0x100000>;
		xlnx,tile0-isp0-iba3-data-format = <16>;
		xlnx,tile1-isp0-iba1-fps = <0>;
		xlnx,tile2-vidout01-tdata-width = <120>;
		xlnx,tile2-isp0-iba2-data-format = <16>;
		xlnx,hdl-tile0-dpll-clkin-period = <0x72719b>;
		xlnx,tile2-common-iba3-ppc = <4>;
		xlnx,tile1-isp1-oba1-mp-bpp = <10>;
		xlnx,tile1-isp0-iba0-res-ver = <2160>;
		xlnx,hdl-tile1-vidin0-tdata-width = <64>;
		xlnx,tile0-dpll-divclk-divide = <1>;
		xlnx,tile0-isp0-core-clk = "600.00";
		xlnx,tile1-isp0-iba0-vcid = <0>;
		xlnx,hdl-tile1-vidout02-bpp = <10>;
		xlnx,hdl-tile0-vidin4-ppc = <4>;
		xlnx,debug-tile1-apb-clk-src-axi;
		xlnx,tile2-isp0-netfps = <0>;
		xlnx,tile2-isp1-oba1-sp-y;
		xlnx,tile0-isp1-oba1-ppc = <4>;
		xlnx,tile0-vidin3-tdata-width = <64>;
		xlnx,hdl-tile2-isp1-iba4-res-hor = <3840>;
		xlnx,tile0-isp1-iba4-res-hor = <3840>;
		xlnx,tile1-common-iba3-res-ver = <2160>;
		xlnx,hdl-tile1-vidout11-bpp = <10>;
		xlnx,debug-tile2-iba1-bypass = <0>;
		xlnx,hdl-tile1-vidout12-ppc = <4>;
		xlnx,tile2-isp0-iba2-vcid = <0>;
		xlnx,tile2-isp0-oba0-sp-rgb888;
		xlnx,tile0-isp0-iba3-fps = <0>;
		xlnx,hdl-tile1-vidin3-data-format = <16>;
		xlnx,tile1-vidin0-tuser-width = <96>;
		xlnx,tile2-isp0-iba1-res-ver = <2160>;
		xlnx,tile0-isp1-io-type = <0>;
		xlnx,tile0-isp1-mem-inputs = <0>;
		xlnx,tile1-isp0-actual-core-clk = <0x2398b390>;
		xlnx,hdl-llpath0-tile = <3>;
		xlnx,tile0-common-iba3-data-format = <16>;
		xlnx,tile0-isp0-oba0-sp-bpp = <10>;
		xlnx,tile0-isp1-iba4-ppc = <4>;
		xlnx,tile1-isp0-oba0-sp-y;
		xlnx,debug-clock-gate = <0>;
		xlnx,tile2-isp1-mem-inputs = <0>;
		xlnx,hdl-tile2-isp1-iba4-vcid = <0>;
		xlnx,hdl-tile0-vidin0-data-format = <16>;
		xlnx,tile2-vidin0-tdata-width = <64>;
		xlnx,tile2-common-iba3-res-hor = <3840>;
		xlnx,tile0-isp1-oba1-sp-rgb888;
		xlnx,tile2-ref-clk = <0x7f27450>;
		xlnx,name = "ISP_hier_visp_ss_tile1_visp_ip";
		xlnx,tile1-isp1-oba1-sp-yuv422;
		xlnx,tile1-isp0-iba1-ppc = <4>;
		xlnx,hdl-tile2-isp0-iba0-res-hor = <3840>;
		xlnx,hdl-tile0-vidout02-bpp = <10>;
		xlnx,tile0-isp0-iba0-res-hor = <3840>;
		xlnx,hdl-tile2-vidin2-tdata-width = <64>;
		xlnx,debug-tile1-iba3-bypass = <0>;
		xlnx,tile0-isp0-oba0-ppc = <4>;
		xlnx,tile0-isp1-iba4-res-ver = <2160>;
		xlnx,hdl-tile1-vidin4-ppc = <4>;
		xlnx,tile0-isp0-iba2-data-format = <16>;
		xlnx,tile0-isp0-oba0-mp-bpp = <10>;
		xlnx,is-hierarchy;
		xlnx,tile2-isp0-iba1-data-format = <16>;
		xlnx,hdl-tile1-dpll-clkfbout-mult = <26>;
		xlnx,hdl-tile0-vidin1-ppc = <4>;
		xlnx,tile0-dpll-clkout3-divide = <4>;
		xlnx,hdl-tile0-vidout11-bpp = <10>;
		xlnx,hdl-tile2-isp-core-1-resolution-mp = <4>;
		xlnx,tile1-isp0-netfps = <60>;
		xlnx,hdl-tile0-vidout12-ppc = <4>;
		xlnx,tile2-isp0-oba0-sp-bpp = <10>;
		xlnx,tile0-vidin2-tdata-width = <64>;
		xlnx,hdl-tile1-isp0-iba0-vcid = <0>;
		xlnx,tile0-isp0-oba0-mp-yuv422;
		xlnx,hdl-tile1-isp-core-0-resolution-mp = <8>;
		xlnx,tile2-common-iba3-res-ver = <2160>;
		xlnx,tile0-isp0-iba3-ppc = <4>;
		xlnx,debug-tile1-iba1-bypass = <0>;
		xlnx,tile1-isp1-iba4-fps = <60>;
		xlnx,hdl-tile0-vidin4-tdata-width = <64>;
		xlnx,tile0-isp0-iba0-fps = <0>;
		xlnx,tile1-isp0-iba1-res-hor = <3840>;
		xlnx,llpath0-tile = <3>;
		xlnx,tile2-isp0-oba0-mp-bpp = <10>;
		xlnx,tile2-isp0-iba1-fps = <0>;
		xlnx,tile0-isp0-iba0-res-ver = <2160>;
		xlnx,hdl-tile1-vidin2-data-format = <16>;
		xlnx,ppc-converter-s2-isp = <0>;
		xlnx,hdl-tile2-vidin4-tuser-width = <96>;
		xlnx,tile1-isp0-core-clk = <0x23988c80>;
		xlnx,hdl-tile0-dpll-clkout-divide2 = <4>;
		xlnx,tile2-dpll-clkfbout-mult = <18>;
		xlnx,hdl-tile2-vidin4-ppc = <4>;
		xlnx,hdl-tile1-isp1-iba4-res-hor = <3840>;
		xlnx,hdl-tile0-dpll-clkout-divide3 = <4>;
		xlnx,tile1-isp1-oba1-sp-rgb888;
		xlnx,tile1-isp1-oba1-ppc = <4>;
		xlnx,tile1-isp1-oba1-mp-y;
		xlnx,tile1-isp1-iba4-vcid = <0>;
		xlnx,tile2-isp1-oba1-sp-yuv422;
		xlnx,hdl-tile1-vidin1-ppc = <4>;
		xlnx,llpath0-clk = <150>;
		xlnx,hdl-tile2-vidin1-tdata-width = <64>;
		xlnx,debug-tile0-iba3-bypass = <0>;
		xlnx,tile2-isp0-rpu = <8>;
		xlnx,tile2-isp0-actual-core-clk = <0x23c31ef0>;
		xlnx,tile0-isp0-iba1-data-format = <16>;
		xlnx,tile0-vidin4-tuser-width = <96>;
		xlnx,tile2-isp0-iba0-data-format = <16>;
		xlnx,hdl-tile1-isp-core-0-frame-rate = <60>;
		xlnx,tile2-isp0-iba2-res-hor = <3840>;
		xlnx,hdl-llpath1-oba = <0>;
		xlnx,tile1-vidin4-tdata-width = <64>;
		xlnx,tile1-isp0-iba3-fps = <0>;
		xlnx,tile1-isp0-iba1-res-ver = <2160>;
		xlnx,tile0-isp0-netfps = <0>;
		xlnx,tile1-dpll-clkout3-divide = <6>;
		xlnx,llpath1-oba = <0>;
		xlnx,tile0-isp0-iba3-vcid = <0>;
		xlnx,tile0-isp0-oba0-mp-y;
		xlnx,tile0-vidin1-tdata-width = <64>;
		xlnx,tile1-isp1-iba4-ppc = <4>;
		xlnx,tile1-isp1-live-inputs = <1>;
		xlnx,tile2-dpll-clkin-period = <0x72719b>;
		xlnx,hdl-tile0-dpll-divclk-divide = <1>;
		xlnx,tile0-isp0-iba0-ppc = <4>;
		xlnx,tile0-isp0-oba0-mp-rgb888;
		xlnx,tile2-isp1-iba3-vcid = <0>;
		xlnx,tile1-isp0-oba0-mp-yuv422;
		xlnx,hdl-tile1-isp0-iba0-res-hor = <3840>;
		xlnx,debug-tile0-iba1-bypass = <0>;
		xlnx,tile2-isp0-iba1-ppc = <4>;
		xlnx,tile0-isp0-iba0-vcid = <0>;
		xlnx,tile0-dpll-clkfbout-fract = <0>;
		xlnx,tile2-isp1-iba4-data-format = <16>;
		xlnx,tile0-isp1-rpu = <6>;
		xlnx,tile1-common-iba3-vcid = <0>;
		xlnx,hdl-tile2-vidout01-bpp = <10>;
		xlnx,hdl-tile2-vidin4-data-format = <16>;
		xlnx,hdl-tile0-vidin3-tdata-width = <64>;
		xlnx,tile0-isp1-core-clk = "600.00";
		xlnx,hdl-tile0-vidout12-tdata-width = <120>;
		xlnx,tile0-isp0-oba0-sp-ir;
		xlnx,hdl-tile2-vidout02-ppc = <4>;
		xlnx,hdl-tile2-isp-core-0-no-of-sensors = <0>;
		xlnx,tile1-isp1-oba1-sp-y;
		xlnx,tile1-isp0-oba0-ppc = <4>;
		xlnx,tile2-isp0-oba0-sp-ir;
		xlnx,hdl-tile1-vidin1-data-format = <16>;
		xlnx,hdl-tile2-vidin1-ppc = <4>;
		xlnx,tile2-isp0-iba2-res-ver = <2160>;
		xlnx,tile1-isp0-iba2-vcid = <0>;
		xlnx,hdl-tile2-vidout11-ppc = <4>;
		xlnx,hdl-tile1-vidin0-tuser-width = <96>;
		xlnx,hdl-tile1-dpll-clkout-divide2 = <6>;
		xlnx,tile0-isp1-oba1-sp-ir;
		xlnx,hdl-tile1-dpll-clkout-divide3 = <6>;
		xlnx,hdl-tile1-isp-core-1-frame-rate = <60>;
		xlnx,tile2-isp1-oba1-sp-rgb888;
		xlnx,tile2-isp1-oba1-sp-ir;
		xlnx,tile0-isp1-iba3-fps = <0>;
		xlnx,hdl-llpath0-tdest-val = <0>;
		xlnx,hdl-tile2-vidin0-tdata-width = <64>;
		xlnx,hdl-tile1-isp-core-1-resolution-mp = <8>;
		xlnx,hdl-llpath1-iba = <0>;
		xlnx,tile0-isp0-oba0-sp-y;
		xlnx,tile1-dpll-divclk-divide = <1>;
		xlnx,tile1-isp0-iba3-ppc = <4>;
		xlnx,tile2-isp1-iba4-fps = <0>;
		xlnx,tile0-isp0-iba0-data-format = <16>;
		xlnx,hdl-tile1-isp1-iba4-vcid = <0>;
		xlnx,tile0-isp0-iba1-res-hor = <3840>;
		xlnx,llpath1-iba = <0>;
		xlnx,tile1-isp0-iba0-fps = <60>;
		xlnx,hdl-tile1-enable;
		xlnx,tile1-vidin3-tdata-width = <64>;
		xlnx,hdl-tile0-isp-core-0-resolution-mp = <4>;
		xlnx,debug-tile2-expose-allintf-allports = <0>;
		xlnx,hdl-tile1-vidout01-bpp = <10>;
		xlnx,edk-iptype = "PERIPHERAL";
		xlnx,hdl-tile0-vidout02-tdata-width = <120>;
		xlnx,hdl-tile0-vidin3-ppc = <4>;
		xlnx,tile2-dpll-clkout3-divide = <4>;
		xlnx,tile0-vidin0-tdata-width = <64>;
		xlnx,tile1-isp0-live-inputs = <1>;
		xlnx,hdl-tile1-vidout02-ppc = <4>;
		xlnx,tile2-isp0-iba1-vcid = <0>;
		xlnx,tile2-isp0-core-clk = "600.00";
		xlnx,hdl-tile0-isp1-iba4-res-hor = <3840>;
		xlnx,tile1-common-iba3-fps = <0>;
		xlnx,tile1-isp0-oba0-mp-rgb888;
		xlnx,tile2-isp1-oba1-ppc = <4>;
		xlnx,tile0-isp1-iba4-data-format = <16>;
		xlnx,tile2-isp1-iba3-res-hor = <3840>;
		xlnx,tile2-isp1-iba3-data-format = <16>;
		xlnx,tile2-isp0-oba0-mp-yuv422;
		xlnx,hdl-tile2-vidin3-data-format = <16>;
		xlnx,hdl-tile0-vidin2-tdata-width = <64>;
		xlnx,tile2-vidin0-tuser-width = <96>;
		xlnx,tile0-isp1-actual-core-clk = <0x23c31ef0>;
		xlnx,tile1-dpll-clkfbout-fract = <56>;
		xlnx,hdl-tile0-vidout11-tdata-width = <120>;
		xlnx,config-only;
		xlnx,hdl-tile1-vidout11-ppc = <4>;
		xlnx,tile0-isp1-oba1-sp-bpp = <10>;
		xlnx,hdl-tile1-vidin0-data-format = <16>;
		xlnx,hdl-tile0-isp0-iba0-vcid = <0>;
		xlnx,tile0-isp0-iba2-fps = <0>;
		xlnx,tile1-isp0-iba2-res-hor = <3840>;
		xlnx,tile1-isp0-iba3-data-format = <16>;
		xlnx,tile0-isp0-iba1-res-ver = <2160>;
		xlnx,hdl-tile0-enabledpll;
		xlnx,tile2-isp0-iba3-fps = <0>;
		xlnx,tile2-config = <0>;
		xlnx,tile0-isp1-oba1-mp-yuv422;
		xlnx,tile0-isp1-iba3-ppc = <4>;
		xlnx,tile1-dpll-clkin-period = <0x72719b>;
		xlnx,hdl-tile1-vidout12-tdata-width = <120>;
		xlnx,tile2-isp1-iba4-ppc = <4>;
		xlnx,debug-tile2-iba4-bypass = <0>;
		xlnx,hdl-tile2-dpll-clkout-divide2 = <4>;
		xlnx,tile0-isp1-oba1-mp-bpp = <10>;
		xlnx,tile0-vidout12-tdata-width = <120>;
		xlnx,tile1-isp0-iba0-ppc = <4>;
		xlnx,hdl-tile2-dpll-clkout-divide3 = <4>;
		xlnx,hdl-tile0-isp0-iba0-res-hor = <3840>;
		xlnx,hdl-tile0-vidout01-bpp = <10>;
		xlnx,tile1-enable;
		xlnx,hdl-tile2-dpll-clkfbout-mult = <18>;
		xlnx,tile1-isp0-mem-inputs = <0>;
		xlnx,hdl-tile0-vidout02-ppc = <4>;
		xlnx,hdl-tile1-vidin3-ppc = <4>;
		xlnx,tile1-isp1-core-clk = <0x23988c80>;
		xlnx,tile2-isp1-netfps = <0>;
		xlnx,tile2-isp1-iba3-res-ver = <2160>;
		xlnx,hdl-tile2-isp-core-1-no-of-sensors = <0>;
		xlnx,tile2-isp0-oba0-ppc = <4>;
		xlnx,tile1-vidin2-tdata-width = <64>;
		xlnx,tile0-isp1-iba4-vcid = <0>;
		xlnx,tile0-isp1-oba1-mp-y;
		xlnx,tile2-isp1-oba1-sp-bpp = <10>;
		xlnx,tile0-config = <0>;
		xlnx,tile1-common-iba3-ppc = <4>;
		xlnx,hdl-tile0-vidin0-ppc = <4>;
		xlnx,tile2-isp0-iba3-res-hor = <3840>;
		xlnx,hdl-tile0-vidin4-tuser-width = <96>;
		xlnx,hdl-tile0-vidout01-tdata-width = <120>;
		xlnx,debug-tile0-expose-scandfx-ports = <0>;
		xlnx,tile1-isp0-iba2-res-ver = <2160>;
		xlnx,hdl-tile0-vidout11-ppc = <4>;
		xlnx,debug-tile0-apb-clk-src-axi;
		xlnx,tile0-dpll-clkfbout-mult = <18>;
		xlnx,hdl-tile1-isp-core-0-no-of-sensors = <1>;
		xlnx,debug-tile2-iba2-bypass = <0>;
		xlnx,hdl-tile1-vidin4-tdata-width = <64>;
		xlnx,debug-tile2-apb-clk-src-axi;
		xlnx,tile0-isp1-iba3-data-format = <16>;
		xlnx,tile2-isp0-oba0-mp-rgb888;
		compatible = "xlnx,visp-2.0";
		xlnx,tile0-isp0-iba2-ppc = <4>;
		xlnx,hdl-tile2-vidin2-data-format = <16>;
		xlnx,hdl-tile0-vidin1-tdata-width = <64>;
		xlnx,tile2-isp1-oba1-mp-bpp = <10>;
		xlnx,tile1-isp1-iba3-fps = <0>;
		xlnx,hdl-tile1-enabledpll;
		xlnx,tile2-isp0-iba3-ppc = <4>;
		xlnx,tile2-dpll-clkfbout-fract = <0>;
		xlnx,hdl-tile1-vidout02-tdata-width = <120>;
		xlnx,tile1-isp1-enable-mp;
		xlnx,tile2-isp0-iba0-fps = <0>;
		xlnx,tile0-vidout02-tdata-width = <120>;
		xlnx,tile1-isp0-iba2-data-format = <16>;
		xlnx,tile1-isp1-iba3-vcid = <0>;
		xlnx,ppc-converter-s1-isp = <0>;
		xlnx,tile0-isp1-oba1-mp-rgb888;
		xlnx,hdl-tile0-isp-core-1-resolution-mp = <4>;
		xlnx,debug-tile2-iba0-bypass = <0>;
		xlnx,tile1-isp1-oba1-mp-yuv422;
		xlnx,tile1-isp1-rpu = <7>;
		xlnx,tile1-isp1-actual-core-clk = <0x2398b390>;
		xlnx,tile1-isp1-mem-inputs = <0>;
		xlnx,hdl-tile1-vidout11-tdata-width = <120>;
		xlnx,tile2-isp0-iba3-res-ver = <2160>;
		xlnx,tile0-isp1-oba1-sp-y;
		xlnx,hdl-tile2-vidout12-bpp = <10>;
		xlnx,hdl-tile2-vidin3-ppc = <4>;
		xlnx,debug-tile1-iba4-bypass = <0>;
		xlnx,tile2-common-iba3-data-format = <16>;
		xlnx,tile1-vidin4-tuser-width = <96>;
		xlnx,tile0-ref-clk = <0x7f27450>;
		xlnx,tile0-vidout11-tdata-width = <120>;
		xlnx,tile1-isp1-iba3-res-hor = <3840>;
		xlnx,hdl-tile1-vidin0-ppc = <4>;
		xlnx,hdl-tile0-vidin4-data-format = <16>;
		xlnx,tile2-vidin4-tdata-width = <64>;
		xlnx,tile0-isp0-iba2-vcid = <0>;
		xlnx,tile1-isp0-oba0-sp-bpp = <10>;
		xlnx,tile1-isp1-netfps = <60>;
		xlnx,tile1-vidin1-tdata-width = <64>;
		xlnx,tile0-isp0-iba2-res-hor = <3840>;
		xlnx,hdl-tile2-vidout12-tdata-width = <120>;
		xlnx,hdl-tile1-dpll-divclk-divide = <1>;
		xlnx,hdl-llpath0-oba = <0>;
		xlnx,debug-tile1-expose-allintf-allports = <0>;
		xlnx,tile1-isp0-iba2-fps = <0>;
		xlnx,tile1-vidout12-tdata-width = <120>;
		xlnx,hdl-tile2-dpll-clkin-period = <0x72719b>;
		xlnx,speedgrade = "-2mp";
		xlnx,llpath0-oba = <0>;
		xlnx,hdl-tile2-enabledpll;
		xlnx,hdl-tile0-isp1-iba4-vcid = <0>;
		xlnx,debug-tile1-iba2-bypass = <0>;
		xlnx,tile2-isp0-io-type = <0>;
		xlnx,tile0-dpll-clkin-period = <0x72719b>;
		xlnx,tile1-isp1-iba3-ppc = <4>;
		xlnx,hdl-tile1-vidin3-tdata-width = <64>;
		xlnx,tile1-isp0-oba0-mp-bpp = <10>;
		xlnx,hdl-tile2-vidin1-data-format = <16>;
		xlnx,hdl-tile0-vidin0-tdata-width = <64>;
		xlnx,tile2-isp0-iba0-ppc = <4>;
		xlnx,tile0-dpll-clkout2-divide = <4>;
		xlnx,tile0-isp0-rpu = <6>;
		xlnx,tile2-isp1-iba4-res-hor = <3840>;
		xlnx,hdl-tile1-vidout01-tdata-width = <120>;
		xlnx,debug-tile1-expose-scandfx-ports = <0>;
		xlnx,tile1-isp0-iba1-vcid = <0>;
		xlnx,hdl-tile2-vidout01-ppc = <4>;
		xlnx,hdl-tile1-vidout12-bpp = <10>;
		xlnx,tile1-isp1-iba3-res-ver = <2160>;
		xlnx,tile2-isp1-core-clk = "600.00";
		xlnx,tile0-isp0-oba0-sp-yuv422;
		xlnx,tile0-vidout01-tdata-width = <120>;
		xlnx,tile1-isp0-iba1-data-format = <16>;
		xlnx,hdl-tile2-vidin0-tuser-width = <96>;
		xlnx,ppc-converter-num-streams = <0>;
		xlnx,tile1-isp0-iba3-res-hor = <3840>;
		xlnx,hdl-tile2-isp-core-0-frame-rate = <30>;
		xlnx,llpath1-delay = <278>;
		xlnx,debug-tile1-iba0-bypass = <0>;
		xlnx,tile1-isp1-oba1-mp-rgb888;
		xlnx,tile0-isp0-iba2-res-ver = <2160>;
		xlnx,hdl-tile2-vidin0-ppc = <4>;
		xlnx,tile2-isp1-oba1-mp-yuv422;
		xlnx,tile2-dpll-divclk-divide = <1>;
		xlnx,debug-tile0-iba4-bypass = <0>;
		xlnx,hdl-tile2-vidout02-tdata-width = <120>;
		xlnx,hdl-tile1-isp-core-1-no-of-sensors = <1>;
		xlnx,hdl-tile0-dpll-clkfbout-fract = <0>;
		xlnx,tile2-isp0-oba0-mp-y;
		xlnx,tile2-isp0-iba3-vcid = <0>;
		xlnx,tile1-vidout02-tdata-width = <120>;
		xlnx,hdl-tile0-vidin3-data-format = <16>;
		xlnx,tile2-vidin3-tdata-width = <64>;
		xlnx,tile0-vidin0-tuser-width = <96>;
		xlnx,hdl-llpath0-iba = <0>;
		xlnx,tile1-isp0-iba2-ppc = <4>;
		xlnx,tile2-isp1-iba3-fps = <0>;
		xlnx,tile1-isp0-io-type = <1>;
		xlnx,hdl-tile0-isp-core-0-no-of-sensors = <0>;
		xlnx,tile2-isp0-iba0-vcid = <0>;
		xlnx,tile0-isp1-live-inputs = <0>;
		xlnx,tile0-isp1-netfps = <0>;
		xlnx,hdl-llpath1-tile = <3>;
		xlnx,tile2-isp1-actual-core-clk = <0x23c31ef0>;
		xlnx,tile1-vidin0-tdata-width = <64>;
		xlnx,llpath0-iba = <0>;
		xlnx,hdl-tile2-vidout11-tdata-width = <120>;
		xlnx,hdl-llpath1-delay = <41>;
		xlnx,tile2-isp0-iba0-res-hor = <3840>;
		xlnx,ip-name = "visp";
		xlnx,tile2-isp1-iba4-res-ver = <2160>;
		xlnx,tile1-vidout11-tdata-width = <120>;
		xlnx,llpath0-delay = <278>;
		xlnx,tile0-common-iba3-vcid = <0>;
		xlnx,hdl-tile0-vidin2-ppc = <4>;
		xlnx,debug-tile0-iba2-bypass = <0>;
		xlnx,hdl-tile1-vidout01-ppc = <4>;
		xlnx,hdl-tile1-vidin2-tdata-width = <64>;
		xlnx,hdl-tile0-vidout12-bpp = <10>;
		xlnx,tile1-isp0-iba3-res-ver = <2160>;
		xlnx,hdl-tile2-vidin0-data-format = <16>;
		xlnx,tile0-isp1-iba3-res-hor = <3840>;
		xlnx,hdl-tile0-dpll-clkfbout-mult = <18>;
		xlnx,hdl-tile2-isp-core-1-frame-rate = <30>;
		xlnx,tile2-vidout12-tdata-width = <120>;
		xlnx,tile1-dpll-clkout2-divide = <6>;
		xlnx,hdl-llpath0-delay = <41>;
		xlnx,tile2-isp0-oba0-sp-y;
		xlnx,tile0-isp0-oba0-sp-rgb888;
		xlnx,tile1-isp0-iba0-data-format = <16>;
		xlnx,tile2-isp1-live-inputs = <0>;
		xlnx,tile0-isp0-iba1-fps = <0>;
		xlnx,tile1-isp0-oba0-sp-ir;
		xlnx,hdl-tile0-isp-core-0-frame-rate = <30>;
		xlnx,tile1-isp0-oba0-sp-yuv422;
		xlnx,debug-tile2-clk-src-dpll;
		xlnx,debug-tile0-iba0-bypass = <0>;
		xlnx,tile2-isp0-iba2-fps = <0>;
		xlnx,hdl-tile1-dpll-clkin-period = <0x72719b>;
		xlnx,tile2-isp0-iba0-res-ver = <2160>;
		xlnx,tile0-isp0-io-type = <0>;
		xlnx,tile2-isp1-oba1-mp-rgb888;
		xlnx,ppc-converter-s3-isp = <0>;
		xlnx,tile2-common-iba3-vcid = <0>;
		xlnx,tile0-common-iba3-res-hor = <3840>;
		xlnx,hdl-tile2-vidout01-tdata-width = <120>;
		xlnx,debug-tile2-expose-scandfx-ports = <0>;
		xlnx,tile2-isp1-iba3-ppc = <4>;
		xlnx,tile1-common-iba3-data-format = <16>;
		xlnx,tile0-isp1-iba3-vcid = <0>;
		xlnx,tile1-vidout01-tdata-width = <120>;
		xlnx,tile1-ref-clk = <0x7f27450>;
		xlnx,hdl-tile1-dpll-clkfbout-fract = <56>;
		xlnx,hdl-tile0-vidin2-data-format = <16>;
		xlnx,tile2-vidin2-tdata-width = <64>;
		xlnx,tile1-isp1-oba1-sp-ir;
		xlnx,llpath1-tile = <3>;
		xlnx,tile1-isp1-iba4-data-format = <16>;
		xlnx,tile1-isp1-iba4-res-hor = <3840>;
		xlnx,hdl-tile1-vidin4-tuser-width = <96>;
		xlnx,hdl-tile0-vidout01-ppc = <4>;
		xlnx,tile0-isp0-live-inputs = <0>;
		xlnx,hdl-tile1-vidin2-ppc = <4>;
		xlnx,llpath1-clk = <150>;
		xlnx,tile0-isp1-iba3-res-ver = <2160>;
		xlnx,tile2-isp1-rpu = <8>;
		xlnx,tile1-dpll-clkfbout-mult = <26>;
		xlnx,hdl-tile2-vidin4-tdata-width = <64>;
		xlnx,debug-tile0-expose-allintf-allports = <0>;
		xlnx,tile0-isp0-iba3-res-hor = <3840>;
		xlnx,hdl-tile2-isp0-iba0-vcid = <0>;
		xlnx,tile2-vidout02-tdata-width = <120>;
		xlnx,tile2-isp0-iba3-data-format = <16>;
		xlnx,hdl-tile1-vidin1-tdata-width = <64>;
		xlnx,tile2-isp1-io-type = <0>;
		xlnx,tile0-common-iba3-fps = <0>;
		xlnx,debug-tile1-clk-src-dpll;
		xlnx,tile2-common-iba3-fps = <0>;
		xlnx,hdl-tile0-isp-core-1-frame-rate = <30>;
		xlnx,tile0-isp0-iba1-ppc = <4>;
		xlnx,tile0-common-iba3-res-ver = <2160>;
		xlnx,tile0-vidin4-tdata-width = <64>;
		xlnx,tile2-vidout11-tdata-width = <120>;
		xlnx,tile0-isp0-actual-core-clk = <0x23c31ef0>;
		xlnx,hdl-llpath1-tdest-val = <0>;
		xlnx,tile2-isp0-iba2-ppc = <4>;
		xlnx,tile2-dpll-clkout2-divide = <4>;
		xlnx,hdl-tile2-vidout02-bpp = <10>;
		xlnx,hdl-tile0-isp-core-1-no-of-sensors = <0>;
		xlnx,tile2-isp0-live-inputs = <0>;
		xlnx,tile1-isp0-iba0-res-hor = <3840>;
		xlnx,tile1-isp0-oba0-sp-rgb888;
		xlnx,tile1-isp1-iba4-res-ver = <2160>;
		xlnx,tile2-vidin4-tuser-width = <96>;
		xlnx,tile2-isp0-oba0-sp-yuv422;
		xlnx,ppc-converter-s0-isp = <0>;
		xlnx,tile2-isp1-oba1-mp-y;
		xlnx,tile2-isp1-iba4-vcid = <0>;
		xlnx,hdl-tile2-isp-core-0-resolution-mp = <4>;
		xlnx,hdl-tile1-vidin4-data-format = <16>;
		xlnx,tile0-isp0-iba1-vcid = <0>;
		xlnx,tile0-isp0-iba3-res-ver = <2160>;
		xlnx,tile1-isp0-rpu = <7>;
		xlnx,hdl-tile2-vidout11-bpp = <10>;
		xlnx,hdl-tile2-vidin2-ppc = <4>;
		xlnx,tile1-common-iba3-res-hor = <3840>;
		xlnx,hdl-tile2-vidout12-ppc = <4>;
		xlnx,hdl-tile0-vidin1-data-format = <16>;
		xlnx,tile2-vidin1-tdata-width = <64>;
		xlnx,tile1-isp1-oba1-sp-bpp = <10>;
		xlnx,tile0-isp1-oba1-sp-yuv422;
	};
	ISP_hier_visp_ss_tile2_visp_ip: ISP_hier_visp_ss_tile2_visp_ip@e8700000 {
		xlnx,hdl-tile2-dpll-divclk-divide = <1>;
		xlnx,hdl-tile2-dpll-clkfbout-fract = <56>;
		xlnx,tile1-config = <0>;
		xlnx,tile1-isp1-iba3-data-format = <16>;
		xlnx,tile0-isp0-mem-inputs = <0>;
		xlnx,tile0-isp1-iba4-fps = <0>;
		xlnx,tile2-isp0-mem-inputs = <0>;
		xlnx,tile1-isp1-io-type = <0>;
		xlnx,hdl-tile2-vidin3-tdata-width = <64>;
		xlnx,hdl-tile0-vidin0-tuser-width = <96>;
		xlnx,debug-tile2-iba3-bypass = <0>;
		xlnx,debug-tile0-clk-src-dpll;
		xlnx,tile1-isp0-iba3-vcid = <0>;
		xlnx,tile1-isp0-oba0-mp-y;
		xlnx,tile2-isp0-iba1-res-hor = <3840>;
		xlnx,tile0-common-iba3-ppc = <4>;
		reg = <0x0 0xe8700000 0x0 0x100000>;
		xlnx,tile0-isp0-iba3-data-format = <16>;
		xlnx,tile1-isp0-iba1-fps = <0>;
		xlnx,tile2-vidout01-tdata-width = <120>;
		xlnx,tile2-isp0-iba2-data-format = <16>;
		xlnx,hdl-tile0-dpll-clkin-period = <0x72719b>;
		xlnx,tile2-common-iba3-ppc = <4>;
		xlnx,tile1-isp0-iba0-res-ver = <2160>;
		xlnx,tile1-isp1-oba1-mp-bpp = <10>;
		xlnx,hdl-tile1-vidin0-tdata-width = <64>;
		xlnx,tile0-dpll-divclk-divide = <1>;
		xlnx,tile0-isp0-core-clk = "600.00";
		xlnx,tile1-isp0-iba0-vcid = <0>;
		xlnx,hdl-tile1-vidout02-bpp = <10>;
		xlnx,hdl-tile0-vidin4-ppc = <4>;
		xlnx,debug-tile1-apb-clk-src-axi;
		xlnx,tile2-isp0-netfps = <60>;
		xlnx,tile2-isp1-oba1-sp-y;
		xlnx,tile0-isp1-oba1-ppc = <4>;
		xlnx,tile0-vidin3-tdata-width = <64>;
		xlnx,hdl-tile2-isp1-iba4-res-hor = <3840>;
		xlnx,tile0-isp1-iba4-res-hor = <3840>;
		xlnx,tile1-common-iba3-res-ver = <2160>;
		xlnx,hdl-tile1-vidout11-bpp = <10>;
		xlnx,debug-tile2-iba1-bypass = <0>;
		xlnx,hdl-tile1-vidout12-ppc = <4>;
		xlnx,tile2-isp0-iba2-vcid = <0>;
		xlnx,tile2-isp0-oba0-sp-rgb888;
		xlnx,tile0-isp0-iba3-fps = <0>;
		xlnx,hdl-tile1-vidin3-data-format = <16>;
		xlnx,tile1-vidin0-tuser-width = <96>;
		xlnx,tile2-isp0-iba1-res-ver = <2160>;
		xlnx,tile0-isp1-io-type = <0>;
		xlnx,tile0-isp1-mem-inputs = <0>;
		xlnx,tile1-isp0-actual-core-clk = <0x23c31ef0>;
		xlnx,hdl-llpath0-tile = <3>;
		xlnx,tile0-common-iba3-data-format = <16>;
		xlnx,tile0-isp0-oba0-sp-bpp = <10>;
		xlnx,tile0-isp1-iba4-ppc = <4>;
		xlnx,tile1-isp0-oba0-sp-y;
		xlnx,debug-clock-gate = <0>;
		xlnx,tile2-isp1-mem-inputs = <0>;
		xlnx,hdl-tile2-isp1-iba4-vcid = <0>;
		xlnx,hdl-tile0-vidin0-data-format = <16>;
		xlnx,tile2-vidin0-tdata-width = <64>;
		xlnx,tile2-common-iba3-res-hor = <3840>;
		xlnx,tile0-isp1-oba1-sp-rgb888;
		xlnx,tile2-ref-clk = <0x7f27450>;
		xlnx,name = "ISP_hier_visp_ss_tile2_visp_ip";
		xlnx,tile1-isp1-oba1-sp-yuv422;
		xlnx,tile1-isp0-iba1-ppc = <4>;
		xlnx,hdl-tile2-isp0-iba0-res-hor = <3840>;
		xlnx,hdl-tile0-vidout02-bpp = <10>;
		xlnx,tile0-isp0-iba0-res-hor = <3840>;
		xlnx,hdl-tile2-vidin2-tdata-width = <64>;
		xlnx,debug-tile1-iba3-bypass = <0>;
		xlnx,tile0-isp0-oba0-ppc = <4>;
		xlnx,tile0-isp1-iba4-res-ver = <2160>;
		xlnx,hdl-tile1-vidin4-ppc = <4>;
		xlnx,tile0-isp0-iba2-data-format = <16>;
		xlnx,tile0-isp0-oba0-mp-bpp = <10>;
		xlnx,is-hierarchy;
		xlnx,tile2-isp0-iba1-data-format = <16>;
		xlnx,hdl-tile1-dpll-clkfbout-mult = <18>;
		xlnx,hdl-tile0-vidin1-ppc = <4>;
		xlnx,tile0-dpll-clkout3-divide = <4>;
		xlnx,hdl-tile0-vidout11-bpp = <10>;
		xlnx,hdl-tile2-isp-core-1-resolution-mp = <8>;
		xlnx,tile1-isp0-netfps = <0>;
		xlnx,hdl-tile0-vidout12-ppc = <4>;
		xlnx,tile2-isp0-oba0-sp-bpp = <10>;
		xlnx,tile0-vidin2-tdata-width = <64>;
		xlnx,hdl-tile1-isp0-iba0-vcid = <0>;
		xlnx,tile0-isp0-oba0-mp-yuv422;
		xlnx,hdl-tile1-isp-core-0-resolution-mp = <4>;
		xlnx,tile2-common-iba3-res-ver = <2160>;
		xlnx,tile0-isp0-iba3-ppc = <4>;
		xlnx,debug-tile1-iba1-bypass = <0>;
		xlnx,tile1-isp1-iba4-fps = <0>;
		xlnx,hdl-tile0-vidin4-tdata-width = <64>;
		xlnx,tile0-isp0-iba0-fps = <0>;
		xlnx,tile1-isp0-iba1-res-hor = <3840>;
		xlnx,llpath0-tile = <3>;
		xlnx,tile2-isp0-oba0-mp-bpp = <10>;
		xlnx,tile2-isp0-iba1-fps = <0>;
		xlnx,tile0-isp0-iba0-res-ver = <2160>;
		xlnx,hdl-tile1-vidin2-data-format = <16>;
		xlnx,ppc-converter-s2-isp = <0>;
		xlnx,hdl-tile2-vidin4-tuser-width = <96>;
		xlnx,tile1-isp0-core-clk = "600.00";
		xlnx,hdl-tile0-dpll-clkout-divide2 = <4>;
		xlnx,tile2-dpll-clkfbout-mult = <26>;
		xlnx,hdl-tile2-vidin4-ppc = <4>;
		xlnx,hdl-tile1-isp1-iba4-res-hor = <3840>;
		xlnx,hdl-tile0-dpll-clkout-divide3 = <4>;
		xlnx,tile1-isp1-oba1-sp-rgb888;
		xlnx,tile1-isp1-oba1-ppc = <4>;
		xlnx,tile1-isp1-iba4-vcid = <0>;
		xlnx,tile1-isp1-oba1-mp-y;
		xlnx,tile2-isp1-oba1-sp-yuv422;
		xlnx,hdl-tile1-vidin1-ppc = <4>;
		xlnx,llpath0-clk = <150>;
		xlnx,hdl-tile2-vidin1-tdata-width = <64>;
		xlnx,debug-tile0-iba3-bypass = <0>;
		xlnx,tile2-isp0-rpu = <8>;
		xlnx,tile2-isp0-actual-core-clk = <0x2398b390>;
		xlnx,tile0-isp0-iba1-data-format = <16>;
		xlnx,tile0-vidin4-tuser-width = <96>;
		xlnx,tile2-isp0-iba0-data-format = <16>;
		xlnx,hdl-tile1-isp-core-0-frame-rate = <30>;
		xlnx,tile2-isp0-iba2-res-hor = <3840>;
		xlnx,hdl-llpath1-oba = <0>;
		xlnx,tile1-vidin4-tdata-width = <64>;
		xlnx,tile1-isp0-iba3-fps = <0>;
		xlnx,tile1-isp0-iba1-res-ver = <2160>;
		xlnx,tile0-isp0-netfps = <0>;
		xlnx,tile1-dpll-clkout3-divide = <4>;
		xlnx,llpath1-oba = <0>;
		xlnx,tile0-isp0-iba3-vcid = <0>;
		xlnx,tile0-isp0-oba0-mp-y;
		xlnx,tile0-vidin1-tdata-width = <64>;
		xlnx,tile1-isp1-iba4-ppc = <4>;
		xlnx,tile1-isp1-live-inputs = <0>;
		xlnx,tile2-dpll-clkin-period = <0x72719b>;
		xlnx,hdl-tile0-dpll-divclk-divide = <1>;
		xlnx,tile2-isp1-enable-mp;
		xlnx,tile0-isp0-iba0-ppc = <4>;
		xlnx,tile0-isp0-oba0-mp-rgb888;
		xlnx,tile2-isp1-iba3-vcid = <0>;
		xlnx,tile1-isp0-oba0-mp-yuv422;
		xlnx,hdl-tile1-isp0-iba0-res-hor = <3840>;
		xlnx,debug-tile0-iba1-bypass = <0>;
		xlnx,tile2-isp0-iba1-ppc = <4>;
		xlnx,tile0-isp0-iba0-vcid = <0>;
		xlnx,tile0-dpll-clkfbout-fract = <0>;
		xlnx,tile2-isp1-iba4-data-format = <16>;
		xlnx,tile0-isp1-rpu = <6>;
		xlnx,tile1-common-iba3-vcid = <0>;
		xlnx,hdl-tile2-vidout01-bpp = <10>;
		xlnx,hdl-tile2-vidin4-data-format = <16>;
		xlnx,hdl-tile0-vidin3-tdata-width = <64>;
		xlnx,tile0-isp1-core-clk = "600.00";
		xlnx,hdl-tile0-vidout12-tdata-width = <120>;
		xlnx,tile0-isp0-oba0-sp-ir;
		xlnx,hdl-tile2-vidout02-ppc = <4>;
		xlnx,hdl-tile2-isp-core-0-no-of-sensors = <1>;
		xlnx,tile1-isp1-oba1-sp-y;
		xlnx,tile1-isp0-oba0-ppc = <4>;
		xlnx,tile2-isp0-oba0-sp-ir;
		xlnx,hdl-tile1-vidin1-data-format = <16>;
		xlnx,hdl-tile2-vidin1-ppc = <4>;
		xlnx,tile2-isp0-iba2-res-ver = <2160>;
		xlnx,tile1-isp0-iba2-vcid = <0>;
		xlnx,hdl-tile2-vidout11-ppc = <4>;
		xlnx,hdl-tile1-vidin0-tuser-width = <96>;
		xlnx,hdl-tile1-dpll-clkout-divide2 = <4>;
		xlnx,tile0-isp1-oba1-sp-ir;
		xlnx,hdl-tile1-dpll-clkout-divide3 = <4>;
		xlnx,hdl-tile1-isp-core-1-frame-rate = <30>;
		xlnx,tile2-isp1-oba1-sp-rgb888;
		xlnx,tile2-isp1-oba1-sp-ir;
		xlnx,tile0-isp1-iba3-fps = <0>;
		xlnx,hdl-llpath0-tdest-val = <0>;
		xlnx,hdl-tile2-vidin0-tdata-width = <64>;
		xlnx,hdl-tile1-isp-core-1-resolution-mp = <4>;
		xlnx,hdl-llpath1-iba = <0>;
		xlnx,tile0-isp0-oba0-sp-y;
		xlnx,tile1-dpll-divclk-divide = <1>;
		xlnx,tile1-isp0-iba3-ppc = <4>;
		xlnx,tile2-isp1-iba4-fps = <60>;
		xlnx,tile0-isp0-iba0-data-format = <16>;
		xlnx,hdl-tile1-isp1-iba4-vcid = <0>;
		xlnx,tile0-isp0-iba1-res-hor = <3840>;
		xlnx,llpath1-iba = <0>;
		xlnx,tile1-isp0-iba0-fps = <0>;
		xlnx,tile1-vidin3-tdata-width = <64>;
		xlnx,hdl-tile0-isp-core-0-resolution-mp = <4>;
		xlnx,debug-tile2-expose-allintf-allports = <0>;
		xlnx,hdl-tile1-vidout01-bpp = <10>;
		xlnx,edk-iptype = "PERIPHERAL";
		xlnx,hdl-tile0-vidout02-tdata-width = <120>;
		xlnx,hdl-tile0-vidin3-ppc = <4>;
		xlnx,tile2-dpll-clkout3-divide = <6>;
		xlnx,tile0-vidin0-tdata-width = <64>;
		xlnx,tile1-isp0-live-inputs = <0>;
		xlnx,hdl-tile1-vidout02-ppc = <4>;
		xlnx,tile2-isp0-iba1-vcid = <0>;
		xlnx,tile2-isp0-core-clk = <0x23988c80>;
		xlnx,hdl-tile0-isp1-iba4-res-hor = <3840>;
		xlnx,tile1-common-iba3-fps = <0>;
		xlnx,tile1-isp0-oba0-mp-rgb888;
		xlnx,tile2-isp1-oba1-ppc = <4>;
		xlnx,tile0-isp1-iba4-data-format = <16>;
		xlnx,tile2-isp1-iba3-res-hor = <3840>;
		xlnx,tile2-isp1-iba3-data-format = <16>;
		xlnx,tile2-isp0-oba0-mp-yuv422;
		xlnx,hdl-tile2-vidin3-data-format = <16>;
		xlnx,hdl-tile0-vidin2-tdata-width = <64>;
		xlnx,tile2-vidin0-tuser-width = <96>;
		xlnx,tile0-isp1-actual-core-clk = <0x23c31ef0>;
		xlnx,tile1-dpll-clkfbout-fract = <0>;
		xlnx,hdl-tile0-vidout11-tdata-width = <120>;
		xlnx,config-only;
		xlnx,hdl-tile1-vidout11-ppc = <4>;
		xlnx,tile0-isp1-oba1-sp-bpp = <10>;
		xlnx,hdl-tile1-vidin0-data-format = <16>;
		xlnx,hdl-tile0-isp0-iba0-vcid = <0>;
		xlnx,tile0-isp0-iba2-fps = <0>;
		xlnx,tile1-isp0-iba2-res-hor = <3840>;
		xlnx,tile1-isp0-iba3-data-format = <16>;
		xlnx,tile0-isp0-iba1-res-ver = <2160>;
		xlnx,hdl-tile0-enabledpll;
		xlnx,tile2-isp0-iba3-fps = <0>;
		xlnx,tile2-config = <0>;
		xlnx,tile0-isp1-oba1-mp-yuv422;
		xlnx,tile0-isp1-iba3-ppc = <4>;
		xlnx,tile1-dpll-clkin-period = <0x72719b>;
		xlnx,hdl-tile1-vidout12-tdata-width = <120>;
		xlnx,tile2-isp1-iba4-ppc = <4>;
		xlnx,debug-tile2-iba4-bypass = <0>;
		xlnx,hdl-tile2-dpll-clkout-divide2 = <6>;
		xlnx,tile0-isp1-oba1-mp-bpp = <10>;
		xlnx,tile0-vidout12-tdata-width = <120>;
		xlnx,tile1-isp0-iba0-ppc = <4>;
		xlnx,hdl-tile2-dpll-clkout-divide3 = <6>;
		xlnx,hdl-tile0-isp0-iba0-res-hor = <3840>;
		xlnx,hdl-tile0-vidout01-bpp = <10>;
		xlnx,hdl-tile2-dpll-clkfbout-mult = <26>;
		xlnx,tile1-isp0-mem-inputs = <0>;
		xlnx,hdl-tile0-vidout02-ppc = <4>;
		xlnx,hdl-tile1-vidin3-ppc = <4>;
		xlnx,tile1-isp1-core-clk = "600.00";
		xlnx,tile2-isp1-netfps = <60>;
		xlnx,tile2-isp1-iba3-res-ver = <2160>;
		xlnx,hdl-tile2-isp-core-1-no-of-sensors = <1>;
		xlnx,tile2-isp0-oba0-ppc = <4>;
		xlnx,tile1-vidin2-tdata-width = <64>;
		xlnx,tile0-isp1-iba4-vcid = <0>;
		xlnx,tile0-isp1-oba1-mp-y;
		xlnx,tile2-isp1-oba1-sp-bpp = <10>;
		xlnx,tile0-config = <0>;
		xlnx,tile1-common-iba3-ppc = <4>;
		xlnx,hdl-tile0-vidin0-ppc = <4>;
		xlnx,tile2-isp0-iba3-res-hor = <3840>;
		xlnx,hdl-tile0-vidin4-tuser-width = <96>;
		xlnx,hdl-tile0-vidout01-tdata-width = <120>;
		xlnx,debug-tile0-expose-scandfx-ports = <0>;
		xlnx,tile1-isp0-iba2-res-ver = <2160>;
		xlnx,hdl-tile0-vidout11-ppc = <4>;
		xlnx,debug-tile0-apb-clk-src-axi;
		xlnx,tile0-dpll-clkfbout-mult = <18>;
		xlnx,hdl-tile1-isp-core-0-no-of-sensors = <0>;
		xlnx,debug-tile2-iba2-bypass = <0>;
		xlnx,hdl-tile1-vidin4-tdata-width = <64>;
		xlnx,debug-tile2-apb-clk-src-axi;
		xlnx,tile0-isp1-iba3-data-format = <16>;
		xlnx,tile2-isp0-oba0-mp-rgb888;
		compatible = "xlnx,visp-2.0";
		xlnx,tile0-isp0-iba2-ppc = <4>;
		xlnx,hdl-tile2-vidin2-data-format = <16>;
		xlnx,hdl-tile0-vidin1-tdata-width = <64>;
		xlnx,tile2-isp1-oba1-mp-bpp = <10>;
		xlnx,tile1-isp1-iba3-fps = <0>;
		xlnx,hdl-tile1-enabledpll;
		xlnx,tile2-isp0-iba3-ppc = <4>;
		xlnx,tile2-dpll-clkfbout-fract = <56>;
		xlnx,hdl-tile1-vidout02-tdata-width = <120>;
		xlnx,tile2-isp0-iba0-fps = <60>;
		xlnx,tile0-vidout02-tdata-width = <120>;
		xlnx,tile1-isp0-iba2-data-format = <16>;
		xlnx,tile1-isp1-iba3-vcid = <0>;
		xlnx,ppc-converter-s1-isp = <0>;
		xlnx,tile0-isp1-oba1-mp-rgb888;
		xlnx,hdl-tile0-isp-core-1-resolution-mp = <4>;
		xlnx,debug-tile2-iba0-bypass = <0>;
		xlnx,tile1-isp1-oba1-mp-yuv422;
		xlnx,tile1-isp1-rpu = <7>;
		xlnx,tile1-isp1-actual-core-clk = <0x23c31ef0>;
		xlnx,tile1-isp1-mem-inputs = <0>;
		xlnx,hdl-tile1-vidout11-tdata-width = <120>;
		xlnx,tile2-isp0-iba3-res-ver = <2160>;
		xlnx,tile0-isp1-oba1-sp-y;
		xlnx,hdl-tile2-vidout12-bpp = <10>;
		xlnx,hdl-tile2-vidin3-ppc = <4>;
		xlnx,debug-tile1-iba4-bypass = <0>;
		xlnx,tile2-common-iba3-data-format = <16>;
		xlnx,tile1-vidin4-tuser-width = <96>;
		xlnx,tile0-ref-clk = <0x7f27450>;
		xlnx,tile0-vidout11-tdata-width = <120>;
		xlnx,tile1-isp1-iba3-res-hor = <3840>;
		xlnx,hdl-tile1-vidin0-ppc = <4>;
		xlnx,hdl-tile0-vidin4-data-format = <16>;
		xlnx,tile2-vidin4-tdata-width = <64>;
		xlnx,tile0-isp0-iba2-vcid = <0>;
		xlnx,tile1-isp0-oba0-sp-bpp = <10>;
		xlnx,tile1-isp1-netfps = <0>;
		xlnx,tile1-vidin1-tdata-width = <64>;
		xlnx,tile0-isp0-iba2-res-hor = <3840>;
		xlnx,hdl-tile2-vidout12-tdata-width = <120>;
		xlnx,hdl-tile1-dpll-divclk-divide = <1>;
		xlnx,hdl-llpath0-oba = <0>;
		xlnx,debug-tile1-expose-allintf-allports = <0>;
		xlnx,tile1-isp0-iba2-fps = <0>;
		xlnx,tile1-vidout12-tdata-width = <120>;
		xlnx,hdl-tile2-dpll-clkin-period = <0x72719b>;
		xlnx,speedgrade = "-2mp";
		xlnx,llpath0-oba = <0>;
		xlnx,hdl-tile2-enabledpll;
		xlnx,hdl-tile0-isp1-iba4-vcid = <0>;
		xlnx,debug-tile1-iba2-bypass = <0>;
		xlnx,tile2-isp0-io-type = <1>;
		xlnx,tile0-dpll-clkin-period = <0x72719b>;
		xlnx,tile1-isp1-iba3-ppc = <4>;
		xlnx,hdl-tile1-vidin3-tdata-width = <64>;
		xlnx,tile1-isp0-oba0-mp-bpp = <10>;
		xlnx,hdl-tile2-vidin1-data-format = <16>;
		xlnx,hdl-tile0-vidin0-tdata-width = <64>;
		xlnx,tile2-isp0-iba0-ppc = <4>;
		xlnx,tile0-dpll-clkout2-divide = <4>;
		xlnx,tile0-isp0-rpu = <6>;
		xlnx,tile2-isp1-iba4-res-hor = <3840>;
		xlnx,hdl-tile1-vidout01-tdata-width = <120>;
		xlnx,debug-tile1-expose-scandfx-ports = <0>;
		xlnx,tile1-isp0-iba1-vcid = <0>;
		xlnx,hdl-tile2-vidout01-ppc = <4>;
		xlnx,hdl-tile1-vidout12-bpp = <10>;
		xlnx,tile1-isp1-iba3-res-ver = <2160>;
		xlnx,tile2-isp1-core-clk = <0x23988c80>;
		xlnx,tile0-isp0-oba0-sp-yuv422;
		xlnx,tile0-vidout01-tdata-width = <120>;
		xlnx,tile1-isp0-iba1-data-format = <16>;
		xlnx,hdl-tile2-vidin0-tuser-width = <96>;
		xlnx,ppc-converter-num-streams = <0>;
		xlnx,tile1-isp0-iba3-res-hor = <3840>;
		xlnx,hdl-tile2-isp-core-0-frame-rate = <60>;
		xlnx,llpath1-delay = <278>;
		xlnx,debug-tile1-iba0-bypass = <0>;
		xlnx,tile0-isp0-iba2-res-ver = <2160>;
		xlnx,tile1-isp1-oba1-mp-rgb888;
		xlnx,hdl-tile2-vidin0-ppc = <4>;
		xlnx,tile2-isp1-oba1-mp-yuv422;
		xlnx,tile2-dpll-divclk-divide = <1>;
		xlnx,debug-tile0-iba4-bypass = <0>;
		xlnx,hdl-tile2-vidout02-tdata-width = <120>;
		xlnx,hdl-tile1-isp-core-1-no-of-sensors = <0>;
		xlnx,tile2-isp0-enable-mp;
		xlnx,hdl-tile0-dpll-clkfbout-fract = <0>;
		xlnx,tile2-isp0-oba0-mp-y;
		xlnx,tile2-isp0-iba3-vcid = <0>;
		xlnx,tile1-vidout02-tdata-width = <120>;
		xlnx,hdl-tile0-vidin3-data-format = <16>;
		xlnx,tile2-vidin3-tdata-width = <64>;
		xlnx,tile0-vidin0-tuser-width = <96>;
		xlnx,hdl-llpath0-iba = <0>;
		xlnx,tile1-isp0-iba2-ppc = <4>;
		xlnx,tile2-isp1-iba3-fps = <0>;
		xlnx,tile1-isp0-io-type = <0>;
		xlnx,hdl-tile0-isp-core-0-no-of-sensors = <0>;
		xlnx,tile2-isp0-iba0-vcid = <0>;
		xlnx,tile0-isp1-live-inputs = <0>;
		xlnx,tile0-isp1-netfps = <0>;
		xlnx,hdl-llpath1-tile = <3>;
		xlnx,tile2-isp1-actual-core-clk = <0x2398b390>;
		xlnx,tile1-vidin0-tdata-width = <64>;
		xlnx,llpath0-iba = <0>;
		xlnx,hdl-tile2-vidout11-tdata-width = <120>;
		xlnx,hdl-llpath1-delay = <41>;
		xlnx,tile2-isp0-iba0-res-hor = <3840>;
		xlnx,ip-name = "visp";
		xlnx,tile2-isp1-iba4-res-ver = <2160>;
		xlnx,tile1-vidout11-tdata-width = <120>;
		xlnx,llpath0-delay = <278>;
		xlnx,tile0-common-iba3-vcid = <0>;
		xlnx,hdl-tile0-vidin2-ppc = <4>;
		xlnx,debug-tile0-iba2-bypass = <0>;
		xlnx,hdl-tile1-vidout01-ppc = <4>;
		xlnx,hdl-tile1-vidin2-tdata-width = <64>;
		xlnx,hdl-tile0-vidout12-bpp = <10>;
		xlnx,tile1-isp0-iba3-res-ver = <2160>;
		xlnx,hdl-tile2-vidin0-data-format = <16>;
		xlnx,tile0-isp1-iba3-res-hor = <3840>;
		xlnx,hdl-tile0-dpll-clkfbout-mult = <18>;
		xlnx,hdl-tile2-isp-core-1-frame-rate = <60>;
		xlnx,tile2-vidout12-tdata-width = <120>;
		xlnx,tile1-dpll-clkout2-divide = <4>;
		xlnx,hdl-llpath0-delay = <41>;
		xlnx,tile2-isp0-oba0-sp-y;
		xlnx,tile0-isp0-oba0-sp-rgb888;
		xlnx,tile1-isp0-iba0-data-format = <16>;
		xlnx,tile2-isp1-live-inputs = <1>;
		xlnx,tile0-isp0-iba1-fps = <0>;
		xlnx,tile1-isp0-oba0-sp-ir;
		xlnx,hdl-tile0-isp-core-0-frame-rate = <30>;
		xlnx,tile1-isp0-oba0-sp-yuv422;
		xlnx,debug-tile2-clk-src-dpll;
		xlnx,debug-tile0-iba0-bypass = <0>;
		xlnx,tile2-isp0-iba2-fps = <0>;
		xlnx,hdl-tile1-dpll-clkin-period = <0x72719b>;
		xlnx,tile2-isp0-iba0-res-ver = <2160>;
		xlnx,tile0-isp0-io-type = <0>;
		xlnx,tile2-isp1-oba1-mp-rgb888;
		xlnx,ppc-converter-s3-isp = <0>;
		xlnx,tile2-common-iba3-vcid = <0>;
		xlnx,tile0-common-iba3-res-hor = <3840>;
		xlnx,hdl-tile2-vidout01-tdata-width = <120>;
		xlnx,debug-tile2-expose-scandfx-ports = <0>;
		xlnx,tile2-isp1-iba3-ppc = <4>;
		xlnx,tile1-common-iba3-data-format = <16>;
		xlnx,tile0-isp1-iba3-vcid = <0>;
		xlnx,tile1-vidout01-tdata-width = <120>;
		xlnx,tile1-ref-clk = <0x7f27450>;
		xlnx,hdl-tile2-enable;
		xlnx,hdl-tile1-dpll-clkfbout-fract = <0>;
		xlnx,hdl-tile0-vidin2-data-format = <16>;
		xlnx,tile2-vidin2-tdata-width = <64>;
		xlnx,tile1-isp1-oba1-sp-ir;
		xlnx,llpath1-tile = <3>;
		xlnx,tile1-isp1-iba4-data-format = <16>;
		xlnx,tile1-isp1-iba4-res-hor = <3840>;
		xlnx,hdl-tile1-vidin4-tuser-width = <96>;
		xlnx,hdl-tile0-vidout01-ppc = <4>;
		xlnx,tile0-isp0-live-inputs = <0>;
		xlnx,hdl-tile1-vidin2-ppc = <4>;
		xlnx,llpath1-clk = <150>;
		xlnx,tile0-isp1-iba3-res-ver = <2160>;
		xlnx,tile2-isp1-rpu = <8>;
		xlnx,tile1-dpll-clkfbout-mult = <18>;
		xlnx,hdl-tile2-vidin4-tdata-width = <64>;
		xlnx,debug-tile0-expose-allintf-allports = <0>;
		xlnx,tile0-isp0-iba3-res-hor = <3840>;
		xlnx,hdl-tile2-isp0-iba0-vcid = <0>;
		xlnx,tile2-vidout02-tdata-width = <120>;
		xlnx,tile2-isp0-iba3-data-format = <16>;
		xlnx,hdl-tile1-vidin1-tdata-width = <64>;
		xlnx,tile2-isp1-io-type = <1>;
		xlnx,tile0-common-iba3-fps = <0>;
		xlnx,debug-tile1-clk-src-dpll;
		xlnx,tile2-common-iba3-fps = <0>;
		xlnx,hdl-tile0-isp-core-1-frame-rate = <30>;
		xlnx,tile0-isp0-iba1-ppc = <4>;
		xlnx,tile0-common-iba3-res-ver = <2160>;
		xlnx,tile0-vidin4-tdata-width = <64>;
		xlnx,tile2-vidout11-tdata-width = <120>;
		xlnx,tile0-isp0-actual-core-clk = <0x23c31ef0>;
		xlnx,hdl-llpath1-tdest-val = <0>;
		xlnx,tile2-isp0-iba2-ppc = <4>;
		xlnx,tile2-dpll-clkout2-divide = <6>;
		xlnx,hdl-tile2-vidout02-bpp = <10>;
		xlnx,hdl-tile0-isp-core-1-no-of-sensors = <0>;
		xlnx,tile2-isp0-live-inputs = <1>;
		xlnx,tile1-isp0-iba0-res-hor = <3840>;
		xlnx,tile1-isp0-oba0-sp-rgb888;
		xlnx,tile1-isp1-iba4-res-ver = <2160>;
		xlnx,tile2-vidin4-tuser-width = <96>;
		xlnx,tile2-isp0-oba0-sp-yuv422;
		xlnx,ppc-converter-s0-isp = <0>;
		xlnx,tile2-isp1-oba1-mp-y;
		xlnx,tile2-isp1-iba4-vcid = <0>;
		xlnx,hdl-tile2-isp-core-0-resolution-mp = <8>;
		xlnx,hdl-tile1-vidin4-data-format = <16>;
		xlnx,tile2-enable;
		xlnx,tile0-isp0-iba1-vcid = <0>;
		xlnx,tile0-isp0-iba3-res-ver = <2160>;
		xlnx,tile1-isp0-rpu = <7>;
		xlnx,hdl-tile2-vidout11-bpp = <10>;
		xlnx,hdl-tile2-vidin2-ppc = <4>;
		xlnx,tile1-common-iba3-res-hor = <3840>;
		xlnx,hdl-tile2-vidout12-ppc = <4>;
		xlnx,hdl-tile0-vidin1-data-format = <16>;
		xlnx,tile2-vidin1-tdata-width = <64>;
		xlnx,tile1-isp1-oba1-sp-bpp = <10>;
		xlnx,tile0-isp1-oba1-sp-yuv422;
	};
	visp_ss_00: visp_ss@e8500000 {
		compatible = "xlnx,visp-ss-lilo-1.0";
		xlnx,io_mode = "lilo";
		xlnx,oba0_sp_data_format = "YUV422";
		xlnx,iba0_data_format = <16>;
		xlnx,iba0_max-width = <3840>;
		xlnx,num_streams = <1>;
		xlnx,oba0_mp_bpp = <10>;
		xlnx,ip-name = "visp_ss";
		xlnx,oba0_mp_ppc = <4>;
		reg = <0x0 0xe8500000 0x0 0x800>;
		xlnx,netfps = <60>;
		xlnx,iba0_frame_rate = <60>;
		isp_id = <0>;
		xlnx,oba0_sp_bpp = <10>;
		xlnx,oba0_sp_ppc = <4>;
		xlnx,iba0_ppc = <4>;
		xlnx,oba0_mp_data_format = "YUV422";
		xlnx,iba0_max-height = <2160>;
		xlnx,rpu = <6>;
		xlnx,name = "visp_ss_00";
		xlnx,mem_inputs = <0>;
		xlnx,iba0_vcid = <0>;
		ports00: ports {
			#address-cells = <1>;
			#size-cells = <0>;
			visp_ss_000ISP_hier_visp_ss_tile0: port@0 {
				reg = <0>;
			};
		};
	};
	visp_ss_01: visp_ss@e8500800 {
		xlnx,iba4_ppc = <4>;
		compatible = "xlnx,visp-ss-lilo-1.0";
		xlnx,iba4_max-height = <2160>;
		xlnx,io_mode = "lilo";
		xlnx,iba4_vcid = <0>;
		xlnx,oba1_sp_bpp = <10>;
		xlnx,num_streams = <1>;
		xlnx,oba1_sp_ppc = <4>;
		xlnx,ip-name = "visp_ss";
		xlnx,oba1_mp_data_format = "YUV422";
		reg = <0x0 0xe8500800 0x0 0x800>;
		xlnx,netfps = <60>;
		xlnx,iba4_data_format = <16>;
		xlnx,iba4_max-width = <3840>;
		isp_id = <1>;
		xlnx,iba4_frame_rate = <60>;
		xlnx,oba1_sp_data_format = "YUV422";
		xlnx,rpu = <6>;
		xlnx,oba1_mp_bpp = <10>;
		xlnx,oba1_mp_ppc = <4>;
		xlnx,name = "visp_ss_01";
		xlnx,mem_inputs = <0>;
		ports01: ports {
			#address-cells = <1>;
			#size-cells = <0>;
			visp_ss_010ISP_hier_visp_ss_tile0: port@0 {
				reg = <0>;
			};
		};
	};
	visp_mbox_rpu_6: visp_mbox_rpu_6 {
		compatible = "xlnx,mbox";
		mboxes = <&ipi_5_to_ipi_3_nobuf 0x0>, <&ipi_5_to_ipi_3_nobuf 0x1>;
		mbox-names = "tx" , "rx";
		rpu_id = <6>;
	};
	visp_ss_12: visp_ss@e8601000 {
		compatible = "xlnx,visp-ss-lilo-1.0";
		xlnx,io_mode = "lilo";
		xlnx,oba0_sp_data_format = "YUV422";
		xlnx,iba0_data_format = <16>;
		xlnx,iba0_max-width = <3840>;
		xlnx,num_streams = <1>;
		xlnx,oba0_mp_bpp = <10>;
		xlnx,ip-name = "visp_ss";
		xlnx,oba0_mp_ppc = <4>;
		reg = <0x0 0xe8601000 0x0 0x800>;
		xlnx,netfps = <60>;
		xlnx,iba0_frame_rate = <60>;
		isp_id = <2>;
		xlnx,oba0_sp_bpp = <10>;
		xlnx,oba0_sp_ppc = <4>;
		xlnx,iba0_ppc = <4>;
		xlnx,oba0_mp_data_format = "YUV422";
		xlnx,iba0_max-height = <2160>;
		xlnx,rpu = <7>;
		xlnx,name = "visp_ss_12";
		xlnx,mem_inputs = <0>;
		xlnx,iba0_vcid = <0>;
		ports12: ports {
			#address-cells = <1>;
			#size-cells = <0>;
			visp_ss_120ISP_hier_visp_ss_tile1: port@0 {
				reg = <0>;
			};
		};
	};
	visp_ss_13: visp_ss@e8601800 {
		xlnx,iba4_ppc = <4>;
		compatible = "xlnx,visp-ss-lilo-1.0";
		xlnx,iba4_max-height = <2160>;
		xlnx,io_mode = "lilo";
		xlnx,iba4_vcid = <0>;
		xlnx,oba1_sp_bpp = <10>;
		xlnx,num_streams = <1>;
		xlnx,oba1_sp_ppc = <4>;
		xlnx,ip-name = "visp_ss";
		xlnx,oba1_mp_data_format = "YUV422";
		reg = <0x0 0xe8601800 0x0 0x800>;
		xlnx,netfps = <60>;
		xlnx,iba4_data_format = <16>;
		xlnx,iba4_max-width = <3840>;
		isp_id = <3>;
		xlnx,iba4_frame_rate = <60>;
		xlnx,oba1_sp_data_format = "YUV422";
		xlnx,rpu = <7>;
		xlnx,oba1_mp_bpp = <10>;
		xlnx,oba1_mp_ppc = <4>;
		xlnx,name = "visp_ss_13";
		xlnx,mem_inputs = <0>;
		ports13: ports {
			#address-cells = <1>;
			#size-cells = <0>;
			visp_ss_130ISP_hier_visp_ss_tile1: port@0 {
				reg = <0>;
			};
		};
	};
	visp_mbox_rpu_7: visp_mbox_rpu_7 {
		compatible = "xlnx,mbox";
		mboxes = <&ipi_5_to_ipi_4_nobuf 0x0>, <&ipi_5_to_ipi_4_nobuf 0x1>;
		mbox-names = "tx" , "rx";
		rpu_id = <7>;
	};
	visp_ss_24: visp_ss@e8702000 {
		compatible = "xlnx,visp-ss-lilo-1.0";
		xlnx,io_mode = "lilo";
		xlnx,oba0_sp_data_format = "YUV422";
		xlnx,iba0_data_format = <16>;
		xlnx,iba0_max-width = <3840>;
		xlnx,num_streams = <1>;
		xlnx,oba0_mp_bpp = <10>;
		xlnx,ip-name = "visp_ss";
		xlnx,oba0_mp_ppc = <4>;
		reg = <0x0 0xe8702000 0x0 0x800>;
		xlnx,netfps = <60>;
		xlnx,iba0_frame_rate = <60>;
		isp_id = <4>;
		xlnx,oba0_sp_bpp = <10>;
		xlnx,oba0_sp_ppc = <4>;
		xlnx,iba0_ppc = <4>;
		xlnx,oba0_mp_data_format = "YUV422";
		xlnx,iba0_max-height = <2160>;
		xlnx,rpu = <8>;
		xlnx,name = "visp_ss_24";
		xlnx,mem_inputs = <0>;
		xlnx,iba0_vcid = <0>;
		ports24: ports {
			#address-cells = <1>;
			#size-cells = <0>;
			visp_ss_240ISP_hier_visp_ss_tile2: port@0 {
				reg = <0>;
			};
		};
	};
	visp_ss_25: visp_ss@e8702800 {
		xlnx,iba4_ppc = <4>;
		compatible = "xlnx,visp-ss-lilo-1.0";
		xlnx,iba4_max-height = <2160>;
		xlnx,io_mode = "lilo";
		xlnx,iba4_vcid = <0>;
		xlnx,oba1_sp_bpp = <10>;
		xlnx,num_streams = <1>;
		xlnx,oba1_sp_ppc = <4>;
		xlnx,ip-name = "visp_ss";
		xlnx,oba1_mp_data_format = "YUV422";
		reg = <0x0 0xe8702800 0x0 0x800>;
		xlnx,netfps = <60>;
		xlnx,iba4_data_format = <16>;
		xlnx,iba4_max-width = <3840>;
		isp_id = <5>;
		xlnx,iba4_frame_rate = <60>;
		xlnx,oba1_sp_data_format = "YUV422";
		xlnx,rpu = <8>;
		xlnx,oba1_mp_bpp = <10>;
		xlnx,oba1_mp_ppc = <4>;
		xlnx,name = "visp_ss_25";
		xlnx,mem_inputs = <0>;
		ports25: ports {
			#address-cells = <1>;
			#size-cells = <0>;
			visp_ss_250ISP_hier_visp_ss_tile2: port@0 {
				reg = <0>;
			};
		};
	};
	visp_mbox_rpu_8: visp_mbox_rpu_8 {
		compatible = "xlnx,mbox";
		mboxes = <&ipi_6_to_ipi_5_nobuf 0x0>, <&ipi_6_to_ipi_5_nobuf 0x1>;
		mbox-names = "tx" , "rx";
		rpu_id = <8>;
	};
	encoder: ale2xx@e8040000 {
		compatible = "al,ale2xx";
		clock-names = "mcu";
		al,devicename = "al_e2xx";
		reg = <0x0 0xe8040000 0x0 0x80000 0x0 0x8000000 0x0 0x8000000>;
		xlnx,mcu-clk = <950>;
		reg-names = "regs" , "apb";
	};
	decoder: ald3xx@e8080000 {
		compatible = "al,ald3xx";
		clock-names = "mcu";
		al,devicename = "al_d3xx";
		reg = <0x0 0xe8080000 0x0 0x80000 0x0 0x00000000 0x0 0x08000000>;
		xlnx,mcu-clk = <918>;
		reg-names = "regs" , "apb";
	};
	aie_core_ref_clk_0: aie_core_ref_clk_0 {
		compatible = "fixed-clock";
		clock-frequency = <1250000000>;
		#clock-cells = <0>;
	};
	zyxclmm_drm {
		interrupts = <0x0 0x89 0x4>, <0x0 0x90 0x4>, <0x0 0x91 0x4>, <0x0 0x92 0x4>, <0x0 0x93 0x4>, <0x0 0x94 0x4>, <0x0 0x95 0x4>, <0x0 0x96 0x4>;
		interrupt-parent = <&gic>;
		compatible = "xlnx,zocl-versal";
	};
};
